VERSION ""

NS_ :

BS_:

BU_: BAP_Tester BedienDisp_vo BedienSG_hi CGS DDA Gateway Gateway_PAG GurtMikrofon OTA_FC ZR_High ZR_LIMU ZR_MIB_TOP_ab_Gen3 ZR_Standard

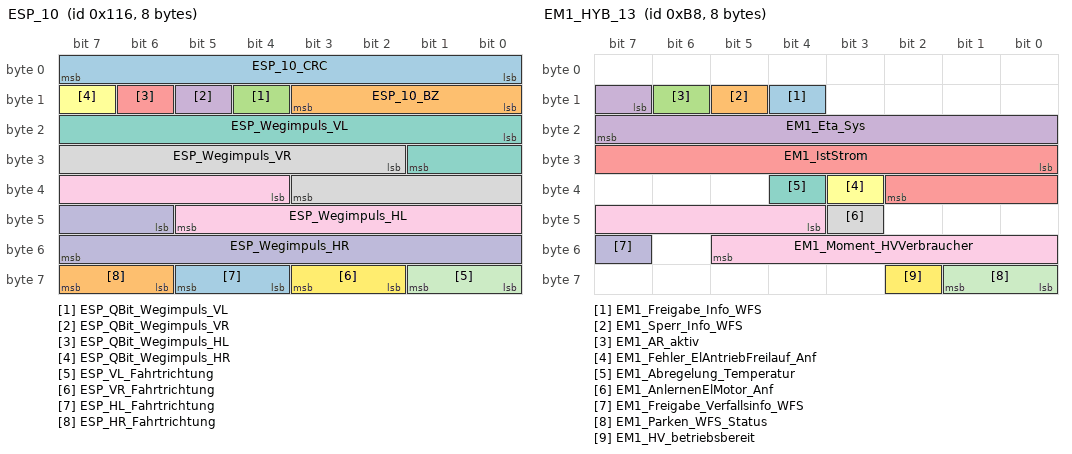
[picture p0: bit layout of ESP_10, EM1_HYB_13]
BO_ 278 ESP_10: 8 Gateway_MQB
 SG_ ESP_10_CRC : 0|8@1+ (1,0) [0|255] "" Airbag_MQB,Motor_Diesel_MQB,Motor_Hybrid_MQB,Motor_Otto_MQB
 SG_ ESP_10_BZ : 8|4@1+ (1,0) [0|15] "" Airbag_MQB,Motor_Diesel_MQB,Motor_Hybrid_MQB,Motor_Otto_MQB
 SG_ ESP_QBit_Wegimpuls_VL : 12|1@1+ (1,0) [0|1] "" Getriebe_DQ_Hybrid_MQB,Getriebe_DQ_MQB,Motor_Diesel_MQB,Motor_Hybrid_MQB,Motor_Otto_MQB
 SG_ ESP_QBit_Wegimpuls_VR : 13|1@1+ (1,0) [0|1] "" Getriebe_DQ_Hybrid_MQB,Getriebe_DQ_MQB,Motor_Diesel_MQB,Motor_Hybrid_MQB,Motor_Otto_MQB
 SG_ ESP_QBit_Wegimpuls_HL : 14|1@1+ (1,0) [0|1] "" Getriebe_DQ_Hybrid_MQB,Getriebe_DQ_MQB,Motor_Diesel_MQB,Motor_Hybrid_MQB,Motor_Otto_MQB
 SG_ ESP_QBit_Wegimpuls_HR : 15|1@1+ (1,0) [0|1] "" Getriebe_DQ_Hybrid_MQB,Getriebe_DQ_MQB,Motor_Diesel_MQB,Motor_Hybrid_MQB,Motor_Otto_MQB
 SG_ ESP_Wegimpuls_VL : 16|10@1+ (1,0) [0|1000] "" Getriebe_DQ_Hybrid_MQB,Getriebe_DQ_MQB,Motor_Diesel_MQB,Motor_Hybrid_MQB,Motor_Otto_MQB
 SG_ ESP_Wegimpuls_VR : 26|10@1+ (1,0) [0|1000] "" Getriebe_DQ_Hybrid_MQB,Getriebe_DQ_MQB,Motor_Diesel_MQB,Motor_Hybrid_MQB,Motor_Otto_MQB
 SG_ ESP_Wegimpuls_HL : 36|10@1+ (1,0) [0|1000] "" Getriebe_DQ_Hybrid_MQB,Getriebe_DQ_MQB,Motor_Diesel_MQB,Motor_Hybrid_MQB,Motor_Otto_MQB
 SG_ ESP_Wegimpuls_HR : 46|10@1+ (1,0) [0|1000] "" Getriebe_DQ_Hybrid_MQB,Getriebe_DQ_MQB,Motor_Diesel_MQB,Motor_Hybrid_MQB,Motor_Otto_MQB
 SG_ ESP_VL_Fahrtrichtung : 56|2@1+ (1,0) [0|3] "" Airbag_MQB,Getriebe_DQ_Hybrid_MQB,Getriebe_DQ_MQB,Motor_Diesel_MQB,Motor_Hybrid_MQB,Motor_Otto_MQB
 SG_ ESP_VR_Fahrtrichtung : 58|2@1+ (1,0) [0|3] "" Airbag_MQB,Getriebe_DQ_Hybrid_MQB,Getriebe_DQ_MQB,Motor_Diesel_MQB,Motor_Hybrid_MQB,Motor_Otto_MQB
 SG_ ESP_HL_Fahrtrichtung : 60|2@1+ (1,0) [0|3] "" Airbag_MQB,Getriebe_DQ_Hybrid_MQB,Getriebe_DQ_MQB,Motor_Diesel_MQB,Motor_Hybrid_MQB,Motor_Otto_MQB
 SG_ ESP_HR_Fahrtrichtung : 62|2@1+ (1,0) [0|3] "" Airbag_MQB,Getriebe_DQ_Hybrid_MQB,Getriebe_DQ_MQB,Motor_Diesel_MQB,Motor_Hybrid_MQB,Motor_Otto_MQB

BO_ 253 ESP_21: 8 Gateway_MQB
 SG_ CHECKSUM : 0|8@1+ (1,0) [0|255] "" Airbag_MQB,Getriebe_DQ_Hybrid_MQB,Getriebe_DQ_MQB,LEH_MQB,Motor_Diesel_MQB,Motor_Hybrid_MQB,Motor_Otto_MQB
 SG_ COUNTER : 8|4@1+ (1,0) [0|15] "" Airbag_MQB,BMS_MQB,Getriebe_DQ_Hybrid_MQB,Getriebe_DQ_MQB,LEH_MQB,Motor_Diesel_MQB,Motor_Hybrid_MQB,Motor_Otto_MQB
 SG_ BR_Eingriffsmoment : 12|10@1+ (1,-509) [-509|509] "Unit_NewtoMeter" Motor_Diesel_MQB,Motor_Hybrid_MQB,Motor_Otto_MQB
 SG_ ESP_v_Signal : 32|16@1+ (0.01,0) [0|655.32] "Unit_KiloMeterPerHour" Airbag_MQB,BMS_MQB,Getriebe_DQ_Hybrid_MQB,Getriebe_DQ_MQB,LEH_MQB,Motor_Diesel_MQB,Motor_Hybrid_MQB,Motor_Otto_MQB,SAK_MQB
 SG_ ASR_Tastung_passiv : 48|1@1+ (1,0) [0|1] "" Airbag_MQB,Getriebe_DQ_Hybrid_MQB,Getriebe_DQ_MQB,Motor_Diesel_MQB,Motor_Hybrid_MQB,Motor_Otto_MQB
 SG_ ESP_Tastung_passiv : 49|1@1+ (1,0) [0|1] "" Airbag_MQB,Getriebe_DQ_Hybrid_MQB,Getriebe_DQ_MQB,Motor_Diesel_MQB,Motor_Hybrid_MQB,Motor_Otto_MQB
 SG_ ESP_Systemstatus : 50|1@1+ (1,0) [0|1] "" Airbag_MQB,Getriebe_DQ_Hybrid_MQB,Getriebe_DQ_MQB,Motor_Diesel_MQB,Motor_Hybrid_MQB,Motor_Otto_MQB
 SG_ ASR_Schalteingriff : 51|2@1+ (1,0) [0|3] "" Getriebe_DQ_Hybrid_MQB,Getriebe_DQ_MQB
 SG_ ESP_Haltebestaetigung : 53|1@1+ (1,0) [0|1] "" Motor_Diesel_MQB,Motor_Hybrid_MQB,Motor_Otto_MQB
 SG_ ESP_QBit_v_Signal : 55|1@1+ (1,0) [0|1] "" Airbag_MQB,Getriebe_DQ_Hybrid_MQB,Getriebe_DQ_MQB,LEH_MQB,Motor_Diesel_MQB,Motor_Hybrid_MQB,Motor_Otto_MQB
 SG_ ABS_Bremsung : 56|1@1+ (1,0) [0|1] "" Airbag_MQB,Getriebe_DQ_Hybrid_MQB,Getriebe_DQ_MQB,Motor_Diesel_MQB,Motor_Hybrid_MQB,Motor_Otto_MQB
 SG_ ASR_Anf : 57|1@1+ (1,0) [0|1] "" Getriebe_DQ_Hybrid_MQB,Getriebe_DQ_MQB,Motor_Diesel_MQB,Motor_Hybrid_MQB,Motor_Otto_MQB
 SG_ MSR_Anf : 58|1@1+ (1,0) [0|1] "" Getriebe_DQ_Hybrid_MQB,Getriebe_DQ_MQB,Motor_Diesel_MQB,Motor_Hybrid_MQB,Motor_Otto_MQB
 SG_ EBV_Eingriff : 59|1@1+ (1,0) [0|1] "" Motor_Diesel_MQB,Motor_Hybrid_MQB,Motor_Otto_MQB
 SG_ EDS_Eingriff : 60|1@1+ (1,0) [0|1] "" Getriebe_DQ_Hybrid_MQB,Getriebe_DQ_MQB,Motor_Diesel_MQB,Motor_Hybrid_MQB,Motor_Otto_MQB
 SG_ ESP_Eingriff : 61|1@1+ (1,0) [0|1] "" Airbag_MQB,Getriebe_DQ_Hybrid_MQB,Getriebe_DQ_MQB,Motor_Diesel_MQB,Motor_Hybrid_MQB,Motor_Otto_MQB
 SG_ ESP_ASP : 62|1@1+ (1,0) [0|1] "" Getriebe_DQ_Hybrid_MQB,Getriebe_DQ_MQB,Motor_Diesel_MQB,Motor_Hybrid_MQB,Motor_Otto_MQB
 SG_ ESP_Anhaltevorgang_ACC_aktiv : 63|1@1+ (1,0) [0|1] "" Motor_Diesel_MQB,Motor_Hybrid_MQB,Motor_Otto_MQB

BO_ 795 ESP_24: 8 Gateway
 SG_ ESP_24_CRC : 0|8@1+ (1,0) [0|255] ""  Sub_Gateway
 SG_ ESP_24_BZ : 8|4@1+ (1,0) [0|15] ""  Sub_Gateway
 SG_ ESP_Lampe : 12|1@1+ (1,0) [0|1] ""  Sub_Gateway
 SG_ ABS_Lampe : 13|1@1+ (1,0) [0|1] ""  Sub_Gateway
 SG_ BK_Lampe_02 : 14|2@1+ (1,0) [0|3] ""  Sub_Gateway
 SG_ TC_Lampe : 16|1@1+ (1,0) [0|1] ""  Sub_Gateway
 SG_ ESP_m_Raddrehz : 17|15@1+ (0.002,0) [0|65.278] "Unit_Hertz"  Sub_Gateway
 SG_ ESP_Textanzeigen_03 : 32|5@1+ (1,0) [0|31] ""  Sub_Gateway
 SG_ ESP_Meldungen : 37|3@1+ (1,0) [0|7] ""  Sub_Gateway
 SG_ ESP_Wegimp_VA : 40|11@1+ (1,0) [0|2047] ""  Sub_Gateway
 SG_ ESP_Fehlerstatus_Wegimp : 51|1@1+ (1,0) [0|1] ""  Sub_Gateway
 SG_ ESP_Wegimp_Ueberlauf : 52|1@1+ (1,0) [0|1] ""  Sub_Gateway
 SG_ ESP_QBit_Wegimp_VA : 53|1@1+ (1,0) [0|1] ""  Sub_Gateway
 SG_ ESP_HDC_Geschw_Farbe : 54|1@1+ (1,0) [0|1] ""  Sub_Gateway
 SG_ ESP_Off_Lampe : 55|1@1+ (1,0) [0|1] ""  Sub_Gateway
 SG_ ESP_HDC_Regelgeschw : 56|7@1+ (0.32,0) [0.32|39.68] "Unit_KiloMeterPerHour"  Sub_Gateway
 SG_ ESP_BKV_Warnung : 63|1@1+ (1,0) [0|1] ""  Sub_Gateway

BO_ 184 EM1_HYB_13: 8 Gateway
 SG_ EM1_Freigabe_Info_WFS : 12|1@1+ (1,0) [0|1] ""  Sub_Gateway
 SG_ EM1_Sperr_Info_WFS : 13|1@1+ (1,0) [0|1] ""  Sub_Gateway
 SG_ EM1_AR_aktiv : 14|1@1+ (1,0) [0|1] ""  Sub_Gateway
 SG_ EM1_Eta_Sys : 15|9@1+ (0.2,0) [0|101.8] "Unit_PerCent"  Sub_Gateway
 SG_ EM1_IstStrom : 24|11@1+ (1,-1023) [-1023|1022] "Unit_Amper"  Sub_Gateway
 SG_ EM1_Fehler_ElAntriebFreilauf_Anf : 35|1@1+ (1,0) [0|1] ""  Sub_Gateway
 SG_ EM1_Abregelung_Temperatur : 36|1@1+ (1,0) [0|1] ""  Sub_Gateway
 SG_ EM1_AnlernenElMotor_Anf : 43|1@1+ (1,0) [0|1] ""  Sub_Gateway
 SG_ EM1_Moment_HVVerbraucher : 44|10@1+ (1,-511) [-511|511] "Unit_NewtoMeter"  Sub_Gateway
 SG_ EM1_Freigabe_Verfallsinfo_WFS : 55|1@1+ (1,0) [0|1] ""  Sub_Gateway
 SG_ EM1_Parken_WFS_Status : 56|2@1+ (1,0) [0|3] ""  Sub_Gateway
 SG_ EM1_HV_betriebsbereit : 58|1@1+ (1,0) [0|1] ""  Sub_Gateway

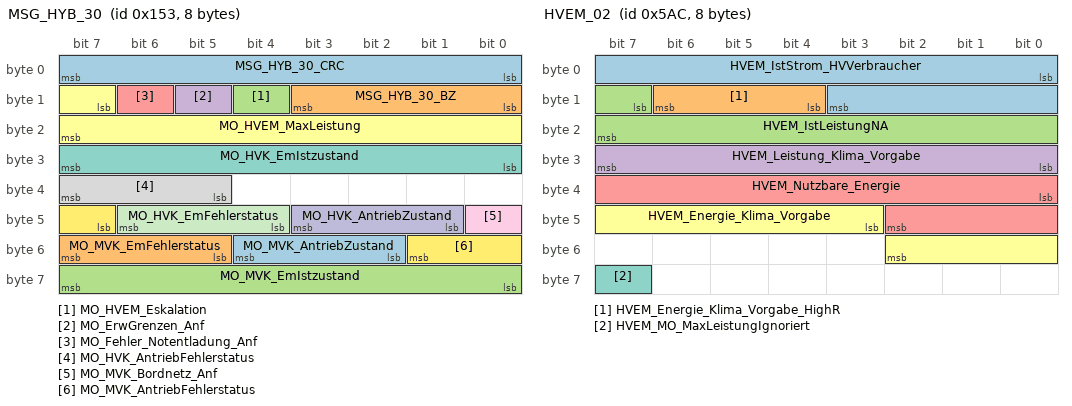
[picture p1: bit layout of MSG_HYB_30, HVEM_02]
BO_ 339 MSG_HYB_30: 8 Gateway
 SG_ MSG_HYB_30_CRC : 0|8@1+ (1,0) [0|255] ""  Ladegeraet_Konzern
 SG_ MSG_HYB_30_BZ : 8|4@1+ (1,0) [0|15] ""  Ladegeraet_Konzern
 SG_ MO_HVEM_Eskalation : 12|1@1+ (1,0) [0|1] "" Vector__XXX
 SG_ MO_ErwGrenzen_Anf : 13|1@1+ (1,0) [0|1] ""  BMC_MLBevo
 SG_ MO_Fehler_Notentladung_Anf : 14|1@1+ (1,0) [0|1] "" Vector__XXX
 SG_ MO_HVEM_MaxLeistung : 15|9@1+ (50,0) [0|25450] "Unit_Watt" Vector__XXX
 SG_ MO_HVK_EmIstzustand : 24|8@1+ (1,0) [0|255] "" Vector__XXX
 SG_ MO_HVK_AntriebFehlerstatus : 37|3@1+ (1,0) [0|7] "" Vector__XXX
 SG_ MO_MVK_Bordnetz_Anf : 40|1@1+ (1,0) [0|1] "" Vector__XXX
 SG_ MO_HVK_AntriebZustand : 41|3@1+ (1,0) [0|7] ""  TME
 SG_ MO_HVK_EmFehlerstatus : 44|3@1+ (1,0) [0|7] "" Vector__XXX
 SG_ MO_MVK_AntriebFehlerstatus : 47|3@1+ (1,0) [0|7] "" Vector__XXX
 SG_ MO_MVK_AntriebZustand : 50|3@1+ (1,0) [0|7] "" Vector__XXX
 SG_ MO_MVK_EmFehlerstatus : 53|3@1+ (1,0) [0|7] "" Vector__XXX
 SG_ MO_MVK_EmIstzustand : 56|8@1+ (1,0) [0|255] "" Vector__XXX

BO_ 1452 HVEM_02: 8 Gateway
 SG_ HVEM_IstStrom_HVVerbraucher : 0|12@1+ (0.1,-204.7) [-204.7|204.6] "Unit_Amper" Vector__XXX
 SG_ HVEM_Energie_Klima_Vorgabe_HighR : 12|3@1+ (10,0) [0|50] "Unit_WattHour"  TME
 SG_ HVEM_IstLeistungNA : 15|9@1+ (50,0) [0|25450] "Unit_Watt" Vector__XXX
 SG_ HVEM_Leistung_Klima_Vorgabe : 24|8@1+ (50,0) [0|12650] "Unit_Watt"  TME
 SG_ HVEM_Nutzbare_Energie : 32|11@1+ (50,0) [0|102200] "Unit_WattHour"  Ladegeraet_Konzern
 SG_ HVEM_Energie_Klima_Vorgabe : 43|8@1+ (50,0) [0|12650] "Unit_WattHour"  TME
 SG_ HVEM_MO_MaxLeistungIgnoriert : 63|1@1+ (1,0) [0|1] "" Vector__XXX

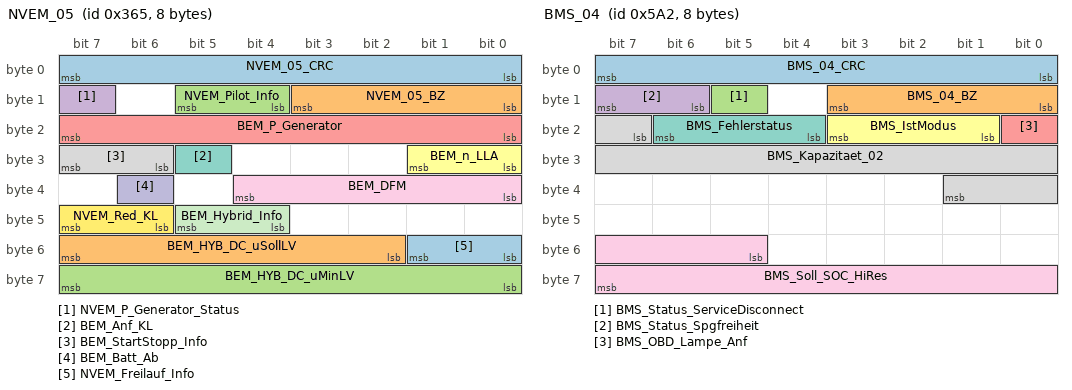
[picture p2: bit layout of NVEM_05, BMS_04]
BO_ 869 NVEM_05: 8 Gateway
 SG_ NVEM_05_CRC : 0|8@1+ (1,0) [0|255] "" Vector__XXX
 SG_ NVEM_05_BZ : 8|4@1+ (1,0) [0|15] "" Vector__XXX
 SG_ NVEM_Pilot_Info : 12|2@1+ (1,0) [0|3] "" Vector__XXX
 SG_ NVEM_P_Generator_Status : 15|1@1+ (1,0) [0|1] "" Vector__XXX
 SG_ BEM_P_Generator : 16|8@1+ (50,0) [0|12700] "Unit_Watt" Vector__XXX
 SG_ BEM_n_LLA : 24|2@1+ (1,0) [0|3] "" Vector__XXX
 SG_ BEM_Anf_KL : 29|1@1+ (1,0) [0|1] "" Vector__XXX
 SG_ BEM_StartStopp_Info : 30|2@1+ (1,0) [0|3] "" Vector__XXX
 SG_ BEM_DFM : 32|5@1+ (3.225,0.025) [0.025|100] "" Vector__XXX
 SG_ BEM_Batt_Ab : 38|1@1+ (1,0) [0|1] ""  DCDC_800V_PAG,DCDC_IHEV
 SG_ BEM_Hybrid_Info : 44|2@1+ (1,0) [0|3] "" Vector__XXX
 SG_ NVEM_Red_KL : 46|2@1+ (1,0) [0|3] ""  TME
 SG_ NVEM_Freilauf_Info : 48|2@1+ (1,0) [0|3] "" Vector__XXX
 SG_ BEM_HYB_DC_uSollLV : 50|6@1+ (0.1,10.6) [10.6|16] "Unit_Volt"  DCDC_800V_PAG,DCDC_HV,LE_MLBevo
 SG_ BEM_HYB_DC_uMinLV : 56|8@1+ (0.1,0) [0|25.3] "Unit_Volt" Vector__XXX

BO_ 1442 BMS_04: 8 BMC_MLBevo
 SG_ BMS_04_CRC : 0|8@1+ (1,0) [0|255] ""  Gateway,Gateway_PAG,Sub_Gateway
 SG_ BMS_04_BZ : 8|4@1+ (1,0) [0|15] ""  Gateway,Gateway_PAG,Sub_Gateway
 SG_ BMS_Status_ServiceDisconnect : 13|1@1+ (1,0) [0|1] ""  DCDC_800V_PAG,DCDC_HV,Gateway,Gateway_PAG,Sub_Gateway
 SG_ BMS_Status_Spgfreiheit : 14|2@1+ (1,0) [0|3] ""  Gateway,Gateway_PAG,Sub_Gateway
 SG_ BMS_OBD_Lampe_Anf : 16|1@1+ (1,0) [0|1] ""  Gateway,Gateway_PAG,Sub_Gateway
 SG_ BMS_IstModus : 17|3@1+ (1,0) [0|7] ""  AWC,Gateway,Gateway_PAG,Ladegeraet_Konzern,LE1,LE2,LE2_3_MLBevo_LB,Sub_Gateway,TME
 SG_ BMS_Fehlerstatus : 20|3@1+ (1,0) [0|7] ""  AWC,DCDC_800V_PAG,DCDC_HV,Gateway,Gateway_PAG,Ladegeraet_Konzern,Sub_Gateway
 SG_ BMS_Kapazitaet_02 : 23|11@1+ (0.2,0) [0|409.2] "Unit_AmperHour"  Gateway,Gateway_PAG,Ladegeraet_Konzern,Sub_Gateway
 SG_ BMS_Soll_SOC_HiRes : 53|11@1+ (0.05,0) [0|100] "Unit_PerCent"  Gateway,Gateway_PAG,Sub_Gateway

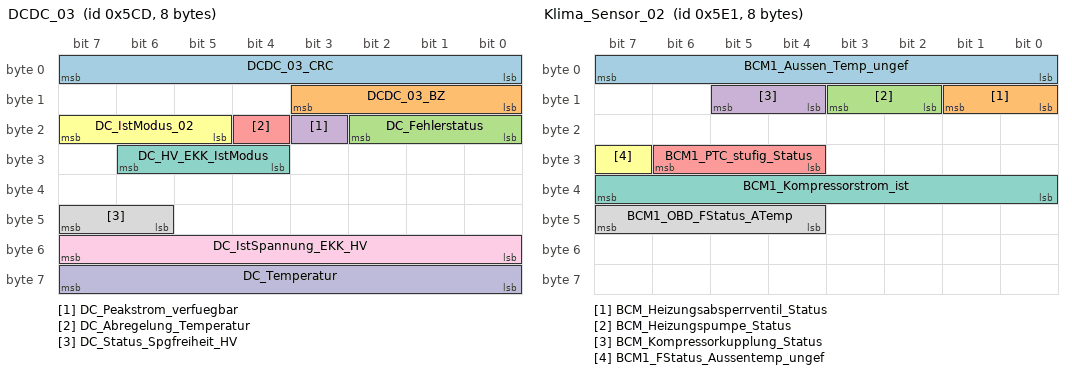
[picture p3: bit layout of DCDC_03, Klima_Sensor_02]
BO_ 1485 DCDC_03: 8 DCDC_800V_PAG
 SG_ DCDC_03_CRC : 0|8@1+ (1,0) [0|255] ""  Gateway,Gateway_PAG,Sub_Gateway
 SG_ DCDC_03_BZ : 8|4@1+ (1,0) [0|15] ""  Gateway,Gateway_PAG,Sub_Gateway
 SG_ DC_Fehlerstatus : 16|3@1+ (1,0) [0|7] ""  Gateway,Gateway_PAG,Sub_Gateway
 SG_ DC_Peakstrom_verfuegbar : 19|1@1+ (1,0) [0|1] ""  Gateway,Gateway_PAG,Sub_Gateway
 SG_ DC_Abregelung_Temperatur : 20|1@1+ (1,0) [0|1] ""  Gateway_PAG,Sub_Gateway,TME
 SG_ DC_IstModus_02 : 21|3@1+ (1,0) [0|7] ""  DCDC_HV_02,Gateway,Gateway_PAG,Ladegeraet_Konzern,Sub_Gateway,TME
 SG_ DC_HV_EKK_IstModus : 28|3@1+ (1,0) [0|7] ""  Gateway,Gateway_PAG,Sub_Gateway,TME
 SG_ DC_Status_Spgfreiheit_HV : 46|2@1+ (1,0) [0|3] ""  Gateway,Gateway_PAG,Sub_Gateway
 SG_ DC_IstSpannung_EKK_HV : 48|8@1+ (2,0) [0|508] "Unit_Volt"  Gateway,Gateway_PAG,Sub_Gateway
 SG_ DC_Temperatur : 56|8@1+ (1,-40) [-40|213] "Unit_DegreCelsi"  Gateway,Gateway_PAG,Sub_Gateway,TME

BO_ 1505 Klima_Sensor_02: 8 Gateway
 SG_ BCM1_Aussen_Temp_ungef : 0|8@1+ (0.5,-50) [-50|76] "Unit_DegreCelsi"  BMC_MLBevo,BMS_NV,FCU_MLBevo_FCEV,Ladegeraet_Konzern,TME
 SG_ BCM_Heizungsabsperrventil_Status : 8|2@1+ (1,0) [0|3] "" Vector__XXX
 SG_ BCM_Heizungspumpe_Status : 10|2@1+ (1,0) [0|3] "" Vector__XXX
 SG_ BCM_Kompressorkupplung_Status : 12|2@1+ (1,0) [0|3] "" Vector__XXX
 SG_ BCM1_PTC_stufig_Status : 28|3@1+ (1,0) [0|7] "" Vector__XXX
 SG_ BCM1_FStatus_Aussentemp_ungef : 31|1@1+ (1,0) [0|1] ""  TME
 SG_ BCM1_Kompressorstrom_ist : 32|8@1+ (4,0) [0|1000] "Unit_MilliAmper" Vector__XXX
 SG_ BCM1_OBD_FStatus_ATemp : 44|4@1+ (1,0) [0|15] ""  BMC_MLBevo,Ladegeraet_Konzern,TME

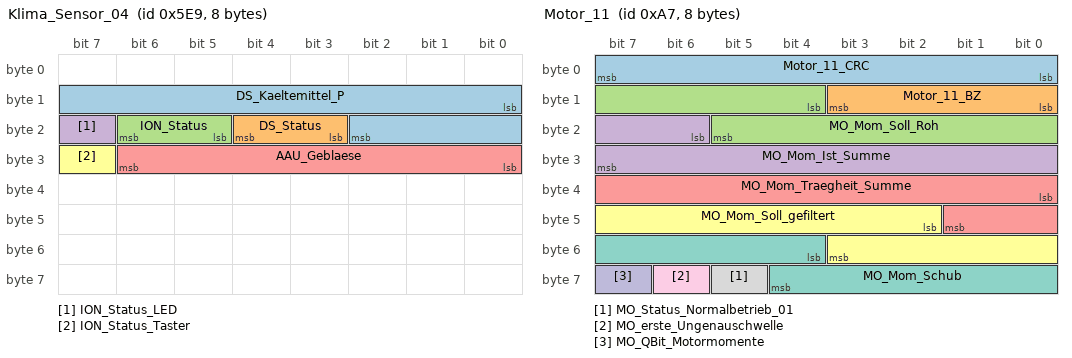
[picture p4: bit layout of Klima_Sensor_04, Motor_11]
BO_ 1513 Klima_Sensor_04: 8 Gateway
 SG_ DS_Kaeltemittel_P : 8|11@1+ (0.0161,0) [0|32.9245] "Unit_Bar"  TME
 SG_ DS_Status : 19|2@1+ (1,0) [0|3] ""  TME
 SG_ ION_Status : 21|2@1+ (1,0) [0|3] "" Vector__XXX
 SG_ ION_Status_LED : 23|1@1+ (1,0) [0|1] "" Vector__XXX
 SG_ AAU_Geblaese : 24|7@1+ (1,0) [0|100] "Unit_PerCent" Vector__XXX
 SG_ ION_Status_Taster : 31|1@1+ (1,0) [0|1] "" Vector__XXX

BO_ 1600 Motor_07: 8 Motor_Diesel_MQB
 SG_ MO_QBit_Ansaugluft_Temp : 0|1@1+ (1,0) [0|1] "" Gateway_MQB
 SG_ MO_QBit_Oel_Temp : 1|1@1+ (1,0) [0|1] "" Gateway_MQB,Getriebe_DQ_Hybrid_MQB,Getriebe_DQ_MQB
 SG_ MO_QBit_Kuehlmittel_Temp : 2|1@1+ (1,0) [0|1] "" Gateway_MQB,Getriebe_DQ_Hybrid_MQB,Getriebe_DQ_MQB,LEH_MQB
 SG_ MO_Stellgliedtest_Soundaktuator : 3|1@1+ (1,0) [0|1] "" Gateway_MQB
 SG_ MO_HYB_Fehler_HV_Netz : 4|1@1+ (1,0) [0|1] "" Gateway_MQB
 SG_ MO_aktives_Getriebeheizen : 5|1@1+ (1,0) [0|1] "" Gateway_MQB,Getriebe_DQ_Hybrid_MQB,Getriebe_DQ_MQB
 SG_ MO_Absperrventil_oeffnen : 6|2@1+ (1,0) [0|3] "" Gateway_MQB
 SG_ MO_Ansaugluft_Temp : 8|8@1+ (0.75,-48) [-48|141.75] "Unit_DegreCelsi" Gateway_MQB
 SG_ MO_Oel_Temp : 16|8@1+ (1,-60) [-60|192] "Unit_DegreCelsi" Gateway_MQB,Getriebe_DQ_Hybrid_MQB,Getriebe_DQ_MQB
 SG_ MO_Kuehlmittel_Temp : 24|8@1+ (0.75,-48) [-48|141.75] "Unit_DegreCelsi" Gateway_MQB,Getriebe_DQ_Hybrid_MQB,Getriebe_DQ_MQB,LEH_MQB
 SG_ MO_Hoeheninfo : 32|8@1+ (0.00781,0) [0|1.98374] "" Gateway_MQB,Getriebe_DQ_Hybrid_MQB,Getriebe_DQ_MQB
 SG_ MO_Kennfeldk : 40|1@1+ (1,0) [0|1] "" Gateway_MQB
 SG_ MO_Versionsinfo : 41|6@1+ (1,0) [0|63] "" Gateway_MQB
 SG_ MO_Getriebe_kuehlen : 47|1@1+ (1,0) [0|1] "" Gateway_MQB,Getriebe_DQ_Hybrid_MQB,Getriebe_DQ_MQB
 SG_ MO_Mom_Traegheit_02 : 48|5@1+ (0.01,0) [0|0.31] "Unit_KiloGramMeterSquar" Gateway_MQB,Getriebe_DQ_Hybrid_MQB,Getriebe_DQ_MQB
 SG_ MO_Heizungspumpenansteuerung : 53|4@1+ (10,0) [0|100] "Unit_PerCent" Gateway_MQB
 SG_ MO_SpannungsAnf : 57|1@1+ (1,0) [0|1] "" Gateway_MQB
 SG_ MO_Nachlaufzeit_Heizungspumpe : 58|6@1+ (15,0) [0|945] "Unit_Secon" Gateway_MQB

BO_ 167 Motor_11: 8 Motor_Diesel_MQB
 SG_ Motor_11_CRC : 0|8@1+ (1,0) [0|255] "" Gateway_MQB,Getriebe_DQ_Hybrid_MQB,Getriebe_DQ_MQB
 SG_ Motor_11_BZ : 8|4@1+ (1,0) [0|15] "" Gateway_MQB,Getriebe_DQ_Hybrid_MQB,Getriebe_DQ_MQB
 SG_ MO_Mom_Soll_Roh : 12|10@1+ (1,-509) [-509|509] "Unit_NewtoMeter" Gateway_MQB,Getriebe_DQ_Hybrid_MQB,Getriebe_DQ_MQB
 SG_ MO_Mom_Ist_Summe : 22|10@1+ (1,-509) [-509|509] "Unit_NewtoMeter" Gateway_MQB,Getriebe_DQ_Hybrid_MQB,Getriebe_DQ_MQB,SAK_MQB
 SG_ MO_Mom_Traegheit_Summe : 32|10@1+ (1,-509) [-509|509] "Unit_NewtoMeter" Gateway_MQB,Getriebe_DQ_Hybrid_MQB,Getriebe_DQ_MQB
 SG_ MO_Mom_Soll_gefiltert : 42|10@1+ (1,-509) [-509|509] "Unit_NewtoMeter" Gateway_MQB,Getriebe_DQ_Hybrid_MQB,Getriebe_DQ_MQB
 SG_ MO_Mom_Schub : 52|9@1+ (1,-509) [-509|0] "Unit_NewtoMeter" Gateway_MQB,Getriebe_DQ_Hybrid_MQB,Getriebe_DQ_MQB
 SG_ MO_Status_Normalbetrieb_01 : 61|1@1+ (1,0) [0|1] "" Gateway_MQB,Getriebe_DQ_Hybrid_MQB,Getriebe_DQ_MQB
 SG_ MO_erste_Ungenauschwelle : 62|1@1+ (1,0) [0|1] "" Gateway_MQB
 SG_ MO_QBit_Motormomente : 63|1@1+ (1,0) [0|1] "" Gateway_MQB,Getriebe_DQ_Hybrid_MQB,Getriebe_DQ_MQB

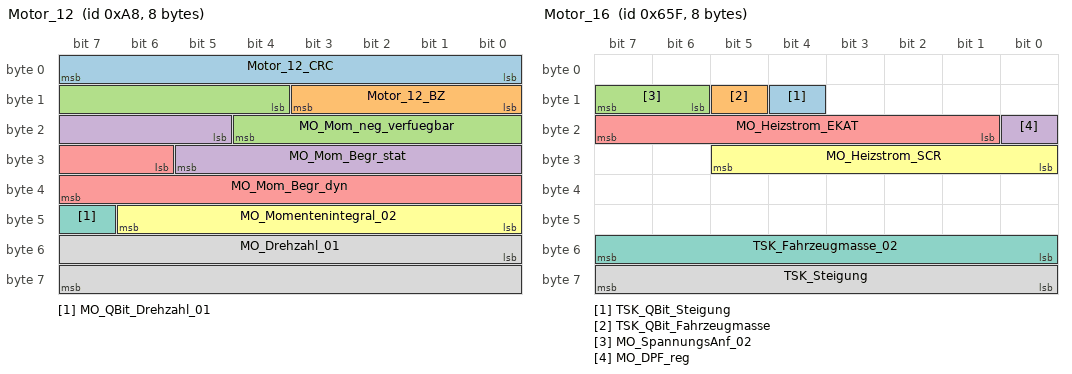
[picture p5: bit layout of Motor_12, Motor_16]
BO_ 168 Motor_12: 8 Motor_Diesel_MQB
 SG_ Motor_12_CRC : 0|8@1+ (1,0) [0|255] "" Gateway_MQB,Getriebe_DQ_Hybrid_MQB,Getriebe_DQ_MQB,LEH_MQB
 SG_ Motor_12_BZ : 8|4@1+ (1,0) [0|15] "" BMS_MQB,Gateway_MQB,Getriebe_DQ_Hybrid_MQB,Getriebe_DQ_MQB,LEH_MQB
 SG_ MO_Mom_neg_verfuegbar : 12|9@1+ (1,-509) [-509|0] "Unit_NewtoMeter" Gateway_MQB
 SG_ MO_Mom_Begr_stat : 21|9@1+ (1,0) [0|509] "Unit_NewtoMeter" Gateway_MQB,Getriebe_DQ_Hybrid_MQB,Getriebe_DQ_MQB
 SG_ MO_Mom_Begr_dyn : 30|10@1+ (1,-509) [-509|509] "Unit_NewtoMeter" Gateway_MQB
 SG_ MO_Momentenintegral_02 : 40|7@1+ (1,0) [0|100] "Unit_PerCent" Gateway_MQB,Getriebe_DQ_Hybrid_MQB,Getriebe_DQ_MQB
 SG_ MO_QBit_Drehzahl_01 : 47|1@1+ (1,0) [0|1] "" BMS_MQB,Gateway_MQB,Getriebe_DQ_Hybrid_MQB,Getriebe_DQ_MQB,LEH_MQB
 SG_ MO_Drehzahl_01 : 48|16@1+ (0.25,0) [0|16383] "Unit_MinutInver" BMS_MQB,Gateway_MQB,Getriebe_DQ_Hybrid_MQB,Getriebe_DQ_MQB,LEH_MQB,SAK_MQB

BO_ 958 Motor_14: 8 Gateway
 SG_ Motor_14_CRC : 0|8@1+ (1,0) [0|255] ""  Sub_Gateway
 SG_ Motor_14_BZ : 8|4@1+ (1,0) [0|15] ""  Sub_Gateway
 SG_ MO_StartStopp_Status : 12|2@1+ (1,0) [0|3] ""  Sub_Gateway,TME
 SG_ MO_StartStopp_Wiederstart : 14|1@1+ (1,0) [0|1] ""  BMS_NV,Sub_Gateway,TME
 SG_ MO_StartStopp_Motorstopp : 15|1@1+ (1,0) [0|1] ""  BMS_NV,Sub_Gateway,TME
 SG_ MO_Freig_Reku : 16|2@1+ (1,0) [0|3] ""  Sub_Gateway
 SG_ MO_Kl_75 : 18|1@1+ (1,0) [0|1] ""  Sub_Gateway,TME
 SG_ MO_Kl_50 : 19|1@1+ (1,0) [0|1] ""  DCDC_IHEV,Ladegeraet_Konzern,Sub_Gateway
 SG_ MO_Gangposition : 20|4@1+ (1,0) [0|15] ""  AWC,Sub_Gateway,TME
 SG_ MO_StartStopp_Fahrerwunsch : 24|2@1+ (1,0) [0|3] ""  Sub_Gateway,TME
 SG_ MO_HYB_Fahrbereitschaft : 26|1@1+ (1,0) [0|1] ""  AWC,BMS_NV,Ladegeraet_Konzern,Sub_Gateway,TME
 SG_ MO_Ext_E_Fahrt_aktiv : 27|1@1+ (1,0) [0|1] ""  Sub_Gateway,TME
 SG_ MO_Fahrer_bremst : 28|1@1+ (1,0) [0|1] ""  Sub_Gateway
 SG_ MO_QBit_Fahrer_bremst : 29|1@1+ (1,0) [0|1] ""  Sub_Gateway
 SG_ MO_BLS : 30|1@1+ (1,0) [0|1] ""  Sub_Gateway
 SG_ MO_Konsistenz_Bremsped : 31|1@1+ (1,0) [0|1] ""  Sub_Gateway
 SG_ MO_KomFehler_ESP : 32|1@1+ (1,0) [0|1] ""  Sub_Gateway
 SG_ MO_Klima_Eingr : 33|2@1+ (1,0) [0|3] ""  Sub_Gateway,TME
 SG_ MO_Aussp_Anlass : 35|1@1+ (1,0) [0|1] ""  Sub_Gateway
 SG_ MO_Freig_Anlass : 36|1@1+ (1,0) [0|1] ""  Sub_Gateway
 SG_ MO_Kuppl_schalter : 37|1@1+ (1,0) [0|1] ""  Sub_Gateway
 SG_ MO_Interlock : 38|1@1+ (1,0) [0|1] ""  Sub_Gateway
 SG_ MO_Motor_laeuft : 39|1@1+ (1,0) [0|1] ""  Sub_Gateway,TME
 SG_ MO_Kickdown : 40|1@1+ (1,0) [0|1] ""  Sub_Gateway,TME
 SG_ MO_QBit_KL_75 : 41|1@1+ (1,0) [0|1] ""  Sub_Gateway
 SG_ MO_EKlKomLeiRed : 42|2@1+ (1,0) [0|3] ""  Sub_Gateway
 SG_ MO_Handshake_STH : 44|1@1+ (1,0) [0|1] ""  Sub_Gateway
 SG_ MO_BKV_Unterdruckwarnung : 45|1@1+ (1,0) [0|1] ""  Sub_Gateway
 SG_ MO_Freigabe_Segeln : 46|1@1+ (1,0) [0|1] ""  Sub_Gateway
 SG_ MO_PTC_Status : 47|3@1+ (1,0) [0|7] ""  Sub_Gateway
 SG_ MO_QBit_Gangposition : 50|1@1+ (1,0) [0|1] ""  Sub_Gateway
 SG_ MO_Signalquelle_Gangposition : 51|1@1+ (1,0) [0|1] ""  Sub_Gateway
 SG_ MO_Remotestart_Betrieb : 52|1@1+ (1,0) [0|1] ""  Sub_Gateway
 SG_ MO_Remotestart_moeglich : 53|1@1+ (1,0) [0|1] ""  Sub_Gateway
 SG_ MO_FMAus_aktiv : 55|1@1+ (1,0) [0|1] ""  BMS_NV,Sub_Gateway
 SG_ MO_FMAus_Startvariante : 56|2@1+ (1,0) [0|3] ""  Sub_Gateway
 SG_ MO_BMS_NV_Anf_stuetzen : 58|1@1+ (1,0) [0|1] ""  Sub_Gateway
 SG_ MO_Zylinderabschaltung : 59|2@1+ (1,0) [0|3] ""  Sub_Gateway
 SG_ MO_HYB_VM_aktiv : 61|1@1+ (1,0) [0|1] ""  Sub_Gateway
 SG_ MO_StartVorauss_erfuellt : 62|2@1+ (1,0) [0|3] ""  AWC,Ladegeraet_Konzern,Sub_Gateway

BO_ 1631 Motor_16: 8 Motor_Diesel_MQB
 SG_ TSK_QBit_Steigung : 12|1@1+ (1,0) [0|1] "" Gateway_MQB,Getriebe_DQ_Hybrid_MQB,Getriebe_DQ_MQB
 SG_ TSK_QBit_Fahrzeugmasse : 13|1@1+ (1,0) [0|1] "" Gateway_MQB,Getriebe_DQ_Hybrid_MQB,Getriebe_DQ_MQB
 SG_ MO_SpannungsAnf_02 : 14|2@1+ (1,0) [0|3] "" Gateway_MQB
 SG_ MO_DPF_reg : 16|1@1+ (1,0) [0|1] "" Gateway_MQB,Getriebe_DQ_Hybrid_MQB,Getriebe_DQ_MQB
 SG_ MO_Heizstrom_EKAT : 17|7@1+ (1,0) [0|126] "Unit_Amper" Gateway_MQB
 SG_ MO_Heizstrom_SCR : 24|6@1+ (1,0) [0|62] "Unit_Amper" Gateway_MQB
 SG_ TSK_Fahrzeugmasse_02 : 48|8@1+ (32,0) [0|8128] "Unit_KiloGram" Gateway_MQB,Getriebe_DQ_Hybrid_MQB,Getriebe_DQ_MQB
 SG_ TSK_Steigung : 56|8@1+ (0.8,-101.6) [-101.6|101.6] "Unit_PerCent" Gateway_MQB,Getriebe_DQ_Hybrid_MQB,Getriebe_DQ_MQB

BO_ 1648 Motor_18: 8 Gateway
 SG_ MO_max_Ladedruck : 0|6@1+ (0.1,0) [0|6.3] "Unit_Bar"  Sub_Gateway
 SG_ MO_ANC_Kennfeld_Anf : 6|2@1+ (1,0) [0|3] ""  Sub_Gateway
 SG_ MO_Bremslicht_Reku : 8|1@1+ (1,0) [0|1] ""  Sub_Gateway
 SG_ MO_StartStopp_PopUp : 9|2@1+ (1,0) [0|3] ""  Sub_Gateway
 SG_ MO1_Sperr_Info_WFS : 11|1@1+ (1,0) [0|1] ""  Sub_Gateway
 SG_ MO1_Freigabe_Info_WFS : 12|1@1+ (1,0) [0|1] ""  Sub_Gateway
 SG_ MO_EPCL : 13|3@1+ (1,0) [0|7] ""  Sub_Gateway
 SG_ MO_Zylabsch_Texte_02 : 16|4@1+ (1,0) [0|15] ""  Sub_Gateway
 SG_ MO_Fahrzeugtyp : 20|3@1+ (1,0) [0|7] ""  BMS_NV,Sub_Gateway
 SG_ MO_NMAX_Schaltanzeige : 23|9@1+ (25,0) [0|12775] "Unit_MinutInver"  Sub_Gateway
 SG_ MO_Abstellzeit : 32|8@1+ (8,0) [0|2024] "Unit_Minut"  BMS_NV,Sub_Gateway,TME
 SG_ MO_Abstellzeit_Status : 40|2@1+ (1,0) [0|3] ""  BMS_NV,Sub_Gateway,TME
 SG_ MO1_Freigabe_Verfallsinfo_WFS : 42|1@1+ (1,0) [0|1] ""  Sub_Gateway
 SG_ MO_Hybrid_StartStopp_LED : 43|2@1+ (1,0) [0|3] ""  Sub_Gateway
 SG_ MO_Fehler_Zylabsch : 45|2@1+ (1,0) [0|3] ""  Sub_Gateway
 SG_ MO_Anzahl_Abgesch_Zyl : 47|3@1+ (1,0) [0|7] ""  Sub_Gateway
 SG_ MO_Zylabsch_Texte : 50|2@1+ (1,0) [0|3] ""  Sub_Gateway
 SG_ MO_Ethanol_BS_Texte : 52|3@1+ (1,0) [0|7] ""  Sub_Gateway
 SG_ MO_Drehzahl_Warnung : 55|1@1+ (1,0) [0|1] ""  Sub_Gateway
 SG_ MO_obere_Drehzahlgrenze : 56|8@1+ (50,0) [50|12750] "Unit_MinutInver"  Sub_Gateway

BO_ 967 Motor_26: 8 Gateway
 SG_ MO_Kuehlerluefter_MUX M : 0|1@1+ (1,0) [0|1] ""  TME
 SG_ MO_Kuehlerluefter_1 m0 : 1|7@1+ (1,0) [0|100] "Unit_PerCent"  TME
 SG_ MO_Kuehlerluefter_2 m1 : 1|7@1+ (1,0) [0|100] "Unit_PerCent"  TME
 SG_ MO_EFLEX_Lampe : 8|2@1+ (1,0) [0|3] "" Vector__XXX
 SG_ MO_KJS_nicht_bereit : 10|1@1+ (1,0) [0|1] "" Vector__XXX
 SG_ MO_ITM_Warnung_Pumpe : 11|1@1+ (1,0) [0|1] "" Vector__XXX
 SG_ WIV_Anzeige_aktiv : 12|1@1+ (1,0) [0|1] "" Vector__XXX
 SG_ WIV_Oelmin_Warn : 13|1@1+ (1,0) [0|1] "" Vector__XXX
 SG_ WIV_Sensorfehler : 14|1@1+ (1,0) [0|1] "" Vector__XXX
 SG_ WIV_Schieflage : 15|1@1+ (1,0) [0|1] "" Vector__XXX
 SG_ WIV_Oelstand : 16|4@1+ (12.5,0) [0|100] "Unit_PerCent" Vector__XXX
 SG_ MO_Zustand_HWP : 20|2@1+ (1,0) [0|3] ""  TME
 SG_ OLEV_Systemstoerung : 22|1@1+ (1,0) [0|1] "" Vector__XXX
 SG_ MO_Oelwarnung_max : 23|1@1+ (1,0) [0|1] "" Vector__XXX
 SG_ WIV_Oelsystem_aktiv : 24|1@1+ (1,0) [0|1] "" Vector__XXX
 SG_ WIV_nicht_betriebswarm : 25|1@1+ (1,0) [0|1] "" Vector__XXX
 SG_ WIV_Ueberfuell_Warn : 26|1@1+ (1,0) [0|1] "" Vector__XXX
 SG_ WIV_laufender_Motor : 27|1@1+ (1,0) [0|1] "" Vector__XXX
 SG_ MO_E_Warnungen : 28|4@1+ (1,0) [0|15] "" Vector__XXX
 SG_ MO_Text_Motorstart : 32|4@1+ (1,0) [0|15] "" Vector__XXX
 SG_ MO_E_Texte : 36|4@1+ (1,0) [0|15] "" Vector__XXX
 SG_ WIV_Oeldyn_avl : 40|1@1+ (1,0) [0|1] "" Vector__XXX
 SG_ MO_Text_Partikelfil_Reg : 41|1@1+ (1,0) [0|1] "" Vector__XXX
 SG_ OLEV_Oelstand_nicht_vorhanden : 42|1@1+ (1,0) [0|1] "" Vector__XXX
 SG_ WIV_Oelmenge : 43|5@1+ (125,0) [0|3875] "Unit_MilliLiter" Vector__XXX
 SG_ MO_Systemlampe : 48|1@1+ (1,0) [0|1] "" Vector__XXX
 SG_ MO_OBD2_Lampe : 49|1@1+ (1,0) [0|1] "" Vector__XXX
 SG_ MO_Heissleuchte : 50|1@1+ (1,0) [0|1] ""  TME
 SG_ MO_Partikel_Lampe : 51|1@1+ (1,0) [0|1] "" Vector__XXX
 SG_ MO_RedFahrleistung_Lampe : 52|1@1+ (1,0) [0|1] "" Vector__XXX
 SG_ WIV_Oelstand_nicht_vorhanden : 53|1@1+ (1,0) [0|1] "" Vector__XXX
 SG_ WIV_nachfuellanzeige_ein : 54|1@1+ (1,0) [0|1] "" Vector__XXX
 SG_ WIV_Ueberfuell_deaktiv : 55|1@1+ (1,0) [0|1] "" Vector__XXX
 SG_ WIV_Unterfuell_Warn : 56|1@1+ (1,0) [0|1] "" Vector__XXX
 SG_ MO_Tankdeckel_Lampe : 57|1@1+ (1,0) [0|1] "" Vector__XXX
 SG_ MO_Text_Tankdeckelwarn : 58|1@1+ (1,0) [0|1] "" Vector__XXX
 SG_ MO_Vorglueh_Lampe : 59|1@1+ (1,0) [0|1] "" Vector__XXX
 SG_ WIV_Oeldr_Warn_Motor : 60|1@1+ (1,0) [0|1] "" Vector__XXX
 SG_ MO_E_Mode : 61|3@1+ (1,0) [0|7] "" Vector__XXX

BO_ 916 WBA_03: 8 Gateway
 SG_ WBA_03_CRC : 0|8@1+ (1,0) [0|255] ""  Sub_Gateway
 SG_ WBA_03_BZ : 8|4@1+ (1,0) [0|15] ""  Sub_Gateway
 SG_ WBA_Fahrstufe_02 : 12|4@1+ (1,0) [0|15] ""  Sub_Gateway
 SG_ WBA_ZielFahrstufe : 16|4@1+ (1,0) [0|15] ""  Sub_Gateway
 SG_ WBA_GE_Warnung_02 : 20|4@1+ (1,0) [0|15] ""  Sub_Gateway
 SG_ WBA_eing_Gang_02 : 24|4@1+ (1,0) [0|15] ""  Sub_Gateway
 SG_ WBA_GE_Texte : 28|3@1+ (1,0) [0|7] ""  Sub_Gateway
 SG_ WBA_Segeln_aktiv : 31|1@1+ (1,0) [0|1] ""  Sub_Gateway
 SG_ WBA_Schaltschema : 32|5@1+ (1,0) [0|31] ""  Sub_Gateway
 SG_ WBA_GE_Zusatzwarnungen : 37|3@1+ (1,0) [0|7] ""  Sub_Gateway
 SG_ GE_Sollgang : 40|4@1+ (1,0) [0|15] ""  Sub_Gateway
 SG_ GE_Tipschaltempf_verfuegbar : 44|1@1+ (1,0) [0|1] ""  Sub_Gateway
 SG_ WBA_GE_Texte_02 : 45|3@1+ (1,0) [0|7] ""  Sub_Gateway
 SG_ WBA_GE_Texte_03 : 48|4@1+ (1,0) [0|15] ""  Sub_Gateway
 SG_ WBA_Blinken : 54|1@1+ (1,0) [0|1] ""  Sub_Gateway
 SG_ GE_Wiederstart_Anz_Std : 55|1@1+ (1,0) [0|1] ""  Sub_Gateway
 SG_ GE_Stoppverbot_Anz_01 : 56|1@1+ (1,0) [0|1] ""  Sub_Gateway
 SG_ GE_Stoppverbot_Anz_02 : 57|1@1+ (1,0) [0|1] ""  Sub_Gateway
 SG_ GE_Stoppverbot_Anz_03 : 58|1@1+ (1,0) [0|1] ""  Sub_Gateway
 SG_ GE_Stoppverbot_Anz_04 : 59|1@1+ (1,0) [0|1] ""  Sub_Gateway
 SG_ GE_Stoppverbot_Anz_05 : 60|1@1+ (1,0) [0|1] ""  Sub_Gateway
 SG_ GE_Stoppverbot_Anz_06 : 61|1@1+ (1,0) [0|1] ""  Sub_Gateway
 SG_ GE_Stoppverbot_Anz_07 : 62|1@1+ (1,0) [0|1] ""  Sub_Gateway
 SG_ GE_Stoppverbot_Anz_Std : 63|1@1+ (1,0) [0|1] ""  Sub_Gateway

BO_ 1283 HVK_01: 8 Gateway
 SG_ HVK_01_CRC : 0|8@1+ (1,0) [0|255] ""  BMC_MLBevo,DCDC_800V_PAG,DCDC_HV,DCDC_HV_02,FCU_MLBevo_FCEV,Ladegeraet_2,Ladegeraet_Konzern,LE1,LE2,LE_MLBevo,TME
 SG_ HVK_01_BZ : 8|4@1+ (1,0) [0|15] ""  BMC_MLBevo,DCDC_800V_PAG,DCDC_HV,DCDC_HV_02,FCU_MLBevo_FCEV,Ladegeraet_2,Ladegeraet_Konzern,LE1,LE2,LE_MLBevo,TME
 SG_ HVK_Istmodus_Anf : 12|1@1+ (1,0) [0|1] ""  BMC_MLBevo,DCDC_HV,FCU_MLBevo_FCEV,Ladegeraet_2,Ladegeraet_Konzern,LE1,LE2,LE_MLBevo
 SG_ HVK_TN1_Sollmodus : 13|2@1+ (1,0) [0|3] ""  DCDC_HV_02,FCU_MLBevo_FCEV
 SG_ HVK_MO_EmSollzustand : 16|8@1+ (1,0) [0|255] ""  FCU_MLBevo_FCEV
 SG_ HVK_BMS_Sollmodus : 24|3@1+ (1,0) [0|7] ""  BMC_MLBevo,FCU_MLBevo_FCEV
 SG_ HVK_DCDC_Sollmodus : 27|3@1+ (1,0) [0|7] ""  DCDC_800V_PAG,DCDC_HV,FCU_MLBevo_FCEV,LE_MLBevo
 SG_ HVK_EKK_Sollmodus : 30|3@1+ (1,0) [0|7] ""  FCU_MLBevo_FCEV,TME
 SG_ HVK_HVPTC_Sollmodus : 33|3@1+ (1,0) [0|7] ""  FCU_MLBevo_FCEV,TME
 SG_ HVK_HVLM_Sollmodus : 36|3@1+ (1,0) [0|7] ""  DCDC_HV_02,FCU_MLBevo_FCEV,Ladegeraet_Konzern
 SG_ HVK_HV_Netz_Warnungen : 39|2@1+ (1,0) [0|3] ""  FCU_MLBevo_FCEV
 SG_ HV_Bordnetz_aktiv : 41|1@1+ (1,0) [0|1] ""  DCDC_HV_02,FCU_MLBevo_FCEV,Ladegeraet_Konzern,LE1,LE2,LE_MLBevo
 SG_ HV_Bordnetz_Fehler : 42|1@1+ (1,0) [0|1] ""  FCU_MLBevo_FCEV,Ladegeraet_Konzern,TME
 SG_ HVK_Gesamtst_Spgfreiheit : 43|2@1+ (1,0) [0|3] ""  FCU_MLBevo_FCEV
 SG_ HVK_AktiveEntladung_Anf : 45|1@1+ (1,0) [0|1] ""  DCDC_800V_PAG,DCDC_HV,DCDC_HV_02,FCU_MLBevo_FCEV,LE1,LE2,LE_MLBevo
 SG_ HVK_Iso_Messung_Start : 50|3@1+ (1,0) [0|7] ""  BMC_MLBevo,FCU_MLBevo_FCEV
 SG_ HVK_DCDC_EKK_Sollmodus : 62|2@1+ (1,0) [0|3] ""  DCDC_800V_PAG,FCU_MLBevo_FCEV

BO_ 949 Klima_11: 8 Gateway
 SG_ KL_Drehz_Anh : 0|1@1+ (1,0) [0|1] ""  TME
 SG_ KL_Vorwarn_Komp_ein : 1|1@1+ (1,0) [0|1] ""  TME
 SG_ KL_AC_Schalter : 2|1@1+ (1,0) [0|1] ""  TME
 SG_ KL_Komp_Moment_alt : 3|1@1+ (1,0) [0|1] ""  TME
 SG_ KL_Vorwarn_Zuheizer_ein : 6|1@1+ (1,0) [0|1] "" Vector__XXX
 SG_ KL_Zustand : 7|1@1+ (1,0) [0|1] ""  TME
 SG_ KL_Kompressorkupplung_linear : 8|8@1+ (20,0) [0|4000] "Unit_MilliAmper" Vector__XXX
 SG_ KL_Charisma_FahrPr : 16|4@1+ (1,0) [0|15] ""  TME
 SG_ KL_Charisma_Status : 20|2@1+ (1,0) [0|3] ""  TME
 SG_ KL_nachtr_Stopp_Anf : 22|1@1+ (1,0) [0|1] "" Vector__XXX
 SG_ KL_T_Charge : 23|1@1+ (1,0) [0|1] "" Vector__XXX
 SG_ KL_Last_Kompr : 24|8@1+ (0.25,0) [0|63.5] "Unit_NewtoMeter"  TME
 SG_ KL_Spannungs_Anf : 32|2@1+ (1,0) [0|3] "" Vector__XXX
 SG_ KL_Thermomanagement : 34|2@1+ (1,0) [0|3] ""  TME
 SG_ KL_StartStopp_Info : 36|2@1+ (1,0) [0|3] ""  TME
 SG_ KL_Freilauf_Info : 38|2@1+ (1,0) [0|3] "" Vector__XXX
 SG_ KL_Anf_KL : 40|8@1+ (0.4,0) [0|101.6] "Unit_PerCent"  TME
 SG_ KL_el_Zuheizer_Stufe : 48|3@1+ (1,0) [0|7] ""  TME
 SG_ KL_Ausstattung_Klima : 51|3@1+ (1,0) [0|7] "" Vector__XXX
 SG_ KL_Variante_Standheizung : 54|2@1+ (1,0) [0|3] "" Vector__XXX

BO_ 1640 Klima_12: 8 Gateway
 SG_ KL_LRH_Taster : 0|1@1+ (1,0) [0|1] "" Vector__XXX
 SG_ KL_LRH_Stufe : 1|2@1+ (1,0) [0|3] "" Vector__XXX
 SG_ HSH_Taster : 3|2@1+ (1,0) [0|3] "" Vector__XXX
 SG_ FSH_Taster : 5|1@1+ (1,0) [0|1] "" Vector__XXX
 SG_ KL_Zuheizer_Freigabe : 6|1@1+ (1,0) [0|1] ""  TME
 SG_ KL_Beschlagsgefahr : 7|1@1+ (1,0) [0|1] ""  TME
 SG_ KL_SIH_Soll_li : 8|3@1+ (1,0) [0|7] ""  TME
 SG_ KL_SIH_Soll_re : 11|3@1+ (1,0) [0|7] ""  TME
 SG_ KRH_Soll_li : 14|2@1+ (1,0) [0|3] "" Vector__XXX
 SG_ KL_SIL_Soll_li : 16|3@1+ (1,0) [0|7] ""  TME
 SG_ KL_SIL_Soll_re : 19|3@1+ (1,0) [0|7] ""  TME
 SG_ KRH_Soll_re : 22|2@1+ (1,0) [0|3] "" Vector__XXX
 SG_ KL_Geblspng_Soll : 24|8@1+ (0.05,1.45) [1.5|14] "Unit_Volt" Vector__XXX
 SG_ KL_Geblspng_Fond_Soll : 32|8@1+ (0.05,1.45) [1.5|14] "Unit_Volt" Vector__XXX
 SG_ KL_I_Geblaese : 40|8@1+ (0.25,0) [0|63.5] "Unit_Amper" Vector__XXX
 SG_ KL_Kompressorstrom_soll : 48|10@1+ (1,0) [0|1021] ""  TME
 SG_ KL_Umluftklappe_Status : 58|4@1+ (1,0) [0|15] ""  TME
 SG_ KL_PTC_Verbauinfo : 62|2@1+ (1,0) [0|3] "" Vector__XXX

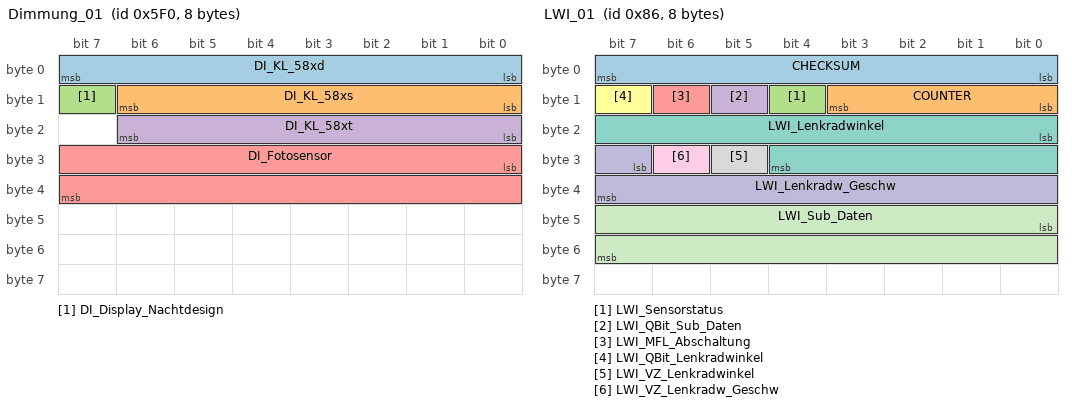
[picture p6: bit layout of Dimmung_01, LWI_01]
BO_ 1520 Dimmung_01: 8 Gateway_MQB
 SG_ DI_KL_58xd : 0|8@1+ (1,0) [0|253] "" Airbag_MQB
 SG_ DI_KL_58xs : 8|7@1+ (1,0) [0|100] "Unit_PerCent" Vector__XXX
 SG_ DI_Display_Nachtdesign : 15|1@1+ (1,0) [0|1] "" Vector__XXX
 SG_ DI_KL_58xt : 16|7@1+ (1,0) [0|100] "Unit_PerCent" Vector__XXX
 SG_ DI_Fotosensor : 24|16@1+ (1,0) [0|65535] "" Vector__XXX

BO_ 870 Blinkmodi_02: 8 Gateway
 SG_ BM_ZV_auf : 12|1@1+ (1.0,0.0) [0.0|1] ""  ZR_High
 SG_ BM_ZV_zu : 13|1@1+ (1.0,0.0) [0.0|1] ""  ZR_High
 SG_ BM_DWA_ein : 14|1@1+ (1.0,0.0) [0.0|1] ""  ZR_High
 SG_ BM_DWA_Alarm : 15|1@1+ (1.0,0.0) [0.0|1] ""  ZR_High
 SG_ BM_Crash : 16|1@1+ (1.0,0.0) [0.0|1] ""  ZR_High
 SG_ BM_Panik : 17|1@1+ (1.0,0.0) [0.0|1] ""  ZR_High
 SG_ BM_Not_Bremsung : 18|1@1+ (1.0,0.0) [0.0|1] ""  ZR_High
 SG_ BM_GDO : 19|1@1+ (1.0,0.0) [0.0|1] ""  Vector__XXX
 SG_ BM_Warnblinken : 20|1@1+ (1.0,0.0) [0.0|1] ""  ZR_High
 SG_ BM_Taxi_Notalarm : 21|1@1+ (1.0,0.0) [0.0|1] ""  ZR_High
 SG_ BM_Telematik : 22|1@1+ (1.0,0.0) [0.0|1] ""  ZR_High
 SG_ BM_links : 23|1@1+ (1.0,0.0) [0.0|1] ""  ZR_High
 SG_ BM_rechts : 24|1@1+ (1.0,0.0) [0.0|1] ""  ZR_High
 SG_ Blinken_li_Fzg_Takt : 25|1@1+ (1.0,0.0) [0.0|1] ""  ZR_High
 SG_ Blinken_re_Fzg_Takt : 26|1@1+ (1.0,0.0) [0.0|1] ""  ZR_High
 SG_ Blinken_li_Kombi_Takt : 27|1@1+ (1.0,0.0) [0.0|1] ""  ZR_High,ZR_LIMU,ZR_MIB_TOP_ab_Gen3,ZR_Standard
 SG_ Blinken_re_Kombi_Takt : 28|1@1+ (1.0,0.0) [0.0|1] ""  ZR_High,ZR_LIMU,ZR_MIB_TOP_ab_Gen3,ZR_Standard
 SG_ BM_NBA_n_codiert_n_aktiv : 29|1@1+ (1.0,0.0) [0.0|1] ""  Vector__XXX
 SG_ BM_NBA_Status : 30|2@1+ (1.0,0.0) [0.0|3] ""  Vector__XXX
 SG_ BM_WBT_Beleuchtung : 32|1@1+ (1.0,0.0) [0.0|1] ""  ZR_High
 SG_ BM_HD_Oeffnung_angelernt : 33|1@1+ (1.0,0.0) [0.0|1] ""  Vector__XXX
 SG_ BM_Autobahn : 34|1@1+ (1.0,0.0) [0.0|1] ""  ZR_High,ZR_LIMU,ZR_MIB_TOP_ab_Gen3
 SG_ BM_Rollenmodus_Blinken : 35|1@1+ (1.0,0.0) [0.0|1] ""  Vector__XXX
 SG_ BM_Recas : 36|1@1+ (1.0,0.0) [0.0|1] ""  ZR_High
 SG_ BM_Wischblinken : 37|1@1+ (1.0,0.0) [0.0|1] ""  ZR_High
 SG_ BM_Telematik_Abbruchgrund : 38|6@1+ (1.0,0.0) [0.0|63] ""  Vector__XXX
 SG_ BM_PiloPa : 44|1@1+ (1.0,0.0) [0.0|1] ""  ZR_High
 SG_ DWA_Alarmquelle : 59|5@1+ (1.0,0.0) [0.0|31] ""  ZR_High

BO_ 982 Licht_hinten_01: 8 Gateway_MQB
 SG_ Licht_hinten_01_BZ : 0|4@1+ (1,0) [0|15] "" Motor_Diesel_MQB,Motor_Hybrid_MQB,Motor_Otto_MQB
 SG_ BCM2_Bremsl_durch_ECD : 5|1@1+ (1,0) [0|1] "" Motor_Diesel_MQB,Motor_Hybrid_MQB,Motor_Otto_MQB
 SG_ LH_Aussenlicht_def : 7|1@1+ (1,0) [0|1] "" Vector__XXX
 SG_ LH_Standlicht_H_aktiv : 8|1@1+ (1,0) [0|1] "" Vector__XXX
 SG_ LH_Parklicht_HL_aktiv : 9|1@1+ (1,0) [0|1] "" Vector__XXX
 SG_ LH_Parklicht_HR_aktiv : 10|1@1+ (1,0) [0|1] "" Vector__XXX
 SG_ LH_Bremslicht_H_aktiv : 11|1@1+ (1,0) [0|1] "" Vector__XXX
 SG_ LH_Nebelschluss_aktiv : 12|1@1+ (1,0) [0|1] "" Vector__XXX
 SG_ LH_Rueckfahrlicht_aktiv : 13|1@1+ (1,0) [0|1] "" Vector__XXX
 SG_ LH_Blinker_HL_akt : 14|1@1+ (1,0) [0|1] "" Vector__XXX
 SG_ LH_Blinker_HR_akt : 15|1@1+ (1,0) [0|1] "" Vector__XXX
 SG_ LH_Blinker_li_def : 16|1@1+ (1,0) [0|1] "" Vector__XXX
 SG_ LH_Bremsl_li_def : 17|1@1+ (1,0) [0|1] "" Vector__XXX
 SG_ LH_Schlusslicht_li_def : 18|1@1+ (1,0) [0|1] "" Vector__XXX
 SG_ LH_Rueckf_li_def : 19|1@1+ (1,0) [0|1] "" Vector__XXX
 SG_ LH_Nebel_li_def : 20|1@1+ (1,0) [0|1] "" Vector__XXX
 SG_ LH_Schluss_Brems_Nebel_li_def : 21|1@1+ (1,0) [0|1] "" Vector__XXX
 SG_ LH_Schluss_Brems_Nebel_re_def : 22|1@1+ (1,0) [0|1] "" Vector__XXX
 SG_ LH_Schluss_Brems_li_def : 24|1@1+ (1,0) [0|1] "" Vector__XXX
 SG_ LH_Schluss_Nebel_li_def : 25|1@1+ (1,0) [0|1] "" Vector__XXX
 SG_ LH_SL_BRL_BLK_li_def : 26|1@1+ (1,0) [0|1] "" Vector__XXX
 SG_ LH_Brems_Blk_li_def : 27|1@1+ (1,0) [0|1] "" Vector__XXX
 SG_ LH_Blinker_re_def : 32|1@1+ (1,0) [0|1] "" Vector__XXX
 SG_ LH_Bremsl_re_def : 33|1@1+ (1,0) [0|1] "" Vector__XXX
 SG_ LH_Schlusslicht_re_def : 34|1@1+ (1,0) [0|1] "" Vector__XXX
 SG_ LH_Rueckf_re_def : 35|1@1+ (1,0) [0|1] "" Vector__XXX
 SG_ LH_Nebel_re_def : 36|1@1+ (1,0) [0|1] "" Vector__XXX
 SG_ LH_Schluss_Brems_re_def : 40|1@1+ (1,0) [0|1] "" Vector__XXX
 SG_ LH_Schluss_Nebel_re_def : 41|1@1+ (1,0) [0|1] "" Vector__XXX
 SG_ LH_SL_BRL_BLK_re_def : 42|1@1+ (1,0) [0|1] "" Vector__XXX
 SG_ LH_Brems_Blk_re_def : 43|1@1+ (1,0) [0|1] "" Vector__XXX
 SG_ LH_Kennzl_def : 48|1@1+ (1,0) [0|1] "" Vector__XXX
 SG_ LH_3_Bremsl_def : 49|1@1+ (1,0) [0|1] "" Motor_Diesel_MQB,Motor_Hybrid_MQB,Motor_Otto_MQB
 SG_ LH_Nebel_mi_def : 50|1@1+ (1,0) [0|1] "" Vector__XXX
 SG_ LH_Rueckf_mi_def : 51|1@1+ (1,0) [0|1] "" Vector__XXX
 SG_ LH_Bremsl_li_ges_def : 54|1@1+ (1,0) [0|1] "" Motor_Diesel_MQB,Motor_Hybrid_MQB,Motor_Otto_MQB
 SG_ LH_Bremsl_re_ges_def : 55|1@1+ (1,0) [0|1] "" Motor_Diesel_MQB,Motor_Hybrid_MQB,Motor_Otto_MQB

BO_ 987 Gateway_72: 8 Gateway_MQB
 SG_ BCM_01_alt : 0|1@1+ (1,0) [0|1] "" Airbag_MQB
 SG_ SMLS_01_alt : 1|1@1+ (1,0) [0|1] "" Motor_Diesel_MQB,Motor_Otto_MQB
 SG_ ZV_02_alt : 2|1@1+ (1,0) [0|1] "" Getriebe_DQ_Hybrid_MQB,Getriebe_DQ_MQB,Motor_Diesel_MQB,Motor_Hybrid_MQB,Motor_Otto_MQB
 SG_ Wischer_01_alt : 3|1@1+ (1,0) [0|1] "" Motor_Diesel_MQB,Motor_Hybrid_MQB,Motor_Otto_MQB
 SG_ Anhaenger_01_alt : 4|1@1+ (1,0) [0|1] "" Getriebe_DQ_Hybrid_MQB,Getriebe_DQ_MQB
 SG_ Klima_Sensor_02_alt : 5|1@1+ (1,0) [0|1] "" Getriebe_DQ_Hybrid_MQB,Getriebe_DQ_MQB,Motor_Diesel_MQB,Motor_Hybrid_MQB,Motor_Otto_MQB
 SG_ VSG_01_alt : 6|1@1+ (1,0) [0|1] "" Airbag_MQB
 SG_ Klima_01_alt : 7|1@1+ (1,0) [0|1] "" Vector__XXX
 SG_ WFS_01_alt : 8|1@1+ (1,0) [0|1] "" Vector__XXX
 SG_ Licht_Anf_01_alt : 9|1@1+ (1,0) [0|1] "" Vector__XXX
 SG_ ZV_HFS_offen : 20|1@1+ (1,0) [0|1] "" Vector__XXX
 SG_ ZV_HBFS_offen : 21|1@1+ (1,0) [0|1] "" Vector__XXX
 SG_ VS_VD_offen_ver : 22|1@1+ (1,0) [0|1] "" Airbag_MQB
 SG_ VS_VD_zu_ver : 23|1@1+ (1,0) [0|1] "" Vector__XXX
 SG_ ZV_BT_offen : 24|1@1+ (1,0) [0|1] "" Vector__XXX
 SG_ BCM1_Rueckfahrlicht_Schalter : 25|1@1+ (1,0) [0|1] "" Airbag_MQB
 SG_ ZV_FT_offen : 26|1@1+ (1,0) [0|1] "" Getriebe_DQ_Hybrid_MQB,Getriebe_DQ_MQB,Motor_Diesel_MQB,Motor_Hybrid_MQB,Motor_Otto_MQB
 SG_ Wischer_vorne_aktiv : 27|1@1+ (1,0) [0|1] "" Motor_Diesel_MQB,Motor_Hybrid_MQB,Motor_Otto_MQB
 SG_ AAG_Anhaenger_erkannt : 28|1@1+ (1,0) [0|1] "" Getriebe_DQ_Hybrid_MQB,Getriebe_DQ_MQB
 SG_ BCM1_MH_Schalter : 29|1@1+ (1,0) [0|1] "" Vector__XXX
 SG_ ZV_HD_offen : 30|1@1+ (1,0) [0|1] "" Vector__XXX
 SG_ Waschen_vorne_aktiv : 31|1@1+ (1,0) [0|1] "" Vector__XXX
 SG_ KL_Thermomanagement : 32|2@1+ (1,0) [0|3] "" Vector__XXX
 SG_ WFS_Schluessel_Fahrberecht : 34|4@1+ (1,0) [0|15] "" Vector__XXX
 SG_ BCM1_RFahrlicht_Fzg_Anf : 38|1@1+ (1,0) [0|1] "" Vector__XXX
 SG_ BCM1_RFahrlicht_Ahg_Anf : 39|1@1+ (1,0) [0|1] "" Vector__XXX
 SG_ BH_Fernlicht : 49|1@1+ (1,0) [0|1] "" Vector__XXX
 SG_ BH_Blinker_li : 50|1@1+ (1,0) [0|1] "" Motor_Diesel_MQB,Motor_Otto_MQB
 SG_ BH_Blinker_re : 51|1@1+ (1,0) [0|1] "" Motor_Diesel_MQB,Motor_Otto_MQB
 SG_ BCM1_OBD_FStatus_ATemp : 52|4@1+ (1,0) [0|15] "" Getriebe_DQ_Hybrid_MQB,Getriebe_DQ_MQB,Motor_Diesel_MQB,Motor_Hybrid_MQB,Motor_Otto_MQB
 SG_ BCM1_Aussen_Temp_ungef : 56|8@1+ (0.5,-50) [-50|76] "Unit_DegreCelsi" Getriebe_DQ_Hybrid_MQB,Getriebe_DQ_MQB,Motor_Diesel_MQB,Motor_Hybrid_MQB,Motor_Otto_MQB

BO_ 299 GRA_ACC_01: 8 Gateway
 SG_ CHECKSUM : 0|8@1+ (1,0) [0|255] ""  Vector__XXX
 SG_ COUNTER : 8|4@1+ (1,0) [0|15] ""  Vector__XXX
 SG_ GRA_Hauptschalter : 12|1@1+ (1.0,0.0) [0.0|1] ""  ZR_High
 SG_ GRA_Abbrechen : 13|1@1+ (1.0,0.0) [0.0|1] ""  ZR_High
 SG_ GRA_Typ_Hauptschalter : 14|1@1+ (1.0,0.0) [0.0|1] ""  ZR_High
 SG_ GRA_Limiter : 15|1@1+ (1.0,0.0) [0.0|1] ""  ZR_High
 SG_ GRA_Tip_Setzen : 16|1@1+ (1.0,0.0) [0.0|1] ""  ZR_High
 SG_ GRA_Tip_Hoch : 17|1@1+ (1.0,0.0) [0.0|1] ""  ZR_High
 SG_ GRA_Tip_Runter : 18|1@1+ (1.0,0.0) [0.0|1] ""  ZR_High
 SG_ GRA_Tip_Wiederaufnahme : 19|1@1+ (1.0,0.0) [0.0|1] ""  ZR_High
 SG_ GRA_Verstellung_Zeitluecke : 20|2@1+ (1.0,0.0) [0.0|3] ""  ZR_High
 SG_ GRA_Codierung : 22|2@1+ (1.0,0.0) [0.0|3] ""  ZR_High
 SG_ GRA_Fehler : 24|1@1+ (1.0,0.0) [0.0|1] ""  ZR_High
 SG_ GRA_LIM_Taste_verfuegbar : 25|1@1+ (1.0,0.0) [0.0|1] ""  ZR_High
 SG_ GRA_Tip_Stufe_2 : 26|1@1+ (1.0,0.0) [0.0|1] ""  ZR_High
 SG_ GRA_ButtonTypeInfo : 27|3@1+ (1.0,0.0) [0.0|7] ""  ZR_High
 SG_ GRA_TravelAssist : 30|1@1+ (1.0,0.0) [0.0|1] ""  Vector__XXX
 SG_ GRA_reserveByte4 : 31|1@1+ (1.0,0.0) [0.0|1] ""  Vector__XXX
 SG_ GRA_reserveByte5 : 32|8@1+ (1.0,0.0) [0.0|255] ""  Vector__XXX
 SG_ GRA_reserveByte6 : 40|8@1+ (1.0,0.0) [0.0|255] ""  Vector__XXX
 SG_ GRA_reserveByte7 : 48|8@1+ (1.0,0.0) [0.0|255] ""  Vector__XXX
 SG_ GRA_reserveByte8 : 56|8@1+ (1.0,0.0) [0.0|255] ""  Vector__XXX

BO_ 134 LWI_01: 8 Gateway
 SG_ CHECKSUM : 0|8@1+ (1,0) [0|255] ""  Vector__XXX
 SG_ COUNTER : 8|4@1+ (1,0) [0|15] ""  Vector__XXX
 SG_ LWI_Sensorstatus : 12|1@1+ (1.0,0.0) [0.0|1] ""  ZR_High,ZR_LIMU,ZR_MIB_TOP_ab_Gen3,ZR_Standard
 SG_ LWI_QBit_Sub_Daten : 13|1@1+ (1.0,0.0) [0.0|1] ""  ZR_High
 SG_ LWI_MFL_Abschaltung : 14|1@1+ (1.0,0.0) [0.0|1] ""  ZR_High
 SG_ LWI_QBit_Lenkradwinkel : 15|1@1+ (1.0,0.0) [0.0|1] ""  ZR_High,ZR_LIMU,ZR_MIB_TOP_ab_Gen3,ZR_Standard
 SG_ LWI_Lenkradwinkel : 16|13@1+ (0.1,0) [0.0|800.0] "Unit_DegreOfArc"  OTA_FC,ZR_High,ZR_LIMU,ZR_MIB_TOP_ab_Gen3,ZR_Standard
 SG_ LWI_VZ_Lenkradwinkel : 29|1@1+ (1.0,0.0) [0.0|1] ""  OTA_FC,ZR_High,ZR_LIMU,ZR_MIB_TOP_ab_Gen3,ZR_Standard
 SG_ LWI_VZ_Lenkradw_Geschw : 30|1@1+ (1.0,0.0) [0.0|1] ""  ZR_High
 SG_ LWI_Lenkradw_Geschw : 31|9@1+ (5,0) [0|2500] "Unit_DegreOfArcPerSecon"  OTA_FC,ZR_High
 SG_ LWI_Sub_Daten : 40|16@1+ (1,0) [0|65535] ""  Vector__XXX

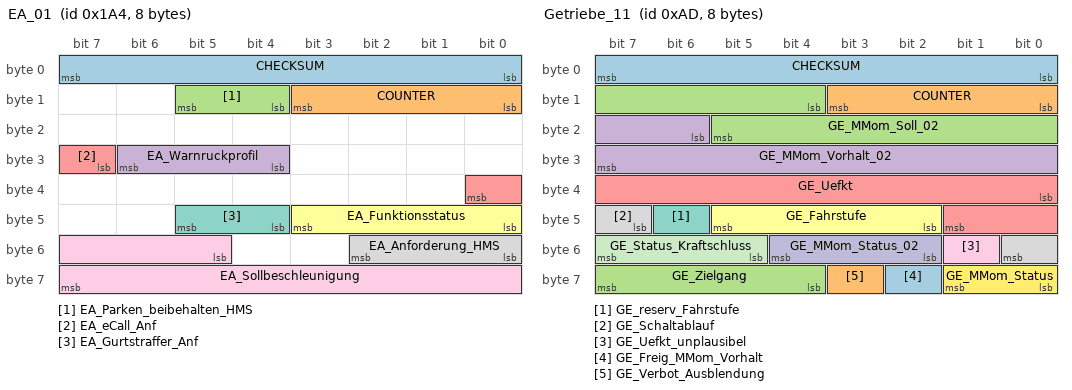
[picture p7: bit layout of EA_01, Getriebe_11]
BO_ 420 EA_01: 8 Gateway
 SG_ CHECKSUM : 0|8@1+ (1,0) [0|255] ""  Vector__XXX
 SG_ COUNTER : 8|4@1+ (1,0) [0|15] ""  Vector__XXX
 SG_ EA_Parken_beibehalten_HMS : 12|2@1+ (1.0,0.0) [0.0|3] ""  Vector__XXX
 SG_ EA_Warnruckprofil : 28|3@1+ (1.0,0.0) [0.0|7] ""  Vector__XXX
 SG_ EA_eCall_Anf : 31|2@1+ (1.0,0.0) [0.0|3] ""  ZR_High
 SG_ EA_Funktionsstatus : 40|4@1+ (1.0,0.0) [0.0|15] ""  ZR_High
 SG_ EA_Gurtstraffer_Anf : 44|2@1+ (1.0,0.0) [0.0|3] ""  Vector__XXX
 SG_ EA_Anforderung_HMS : 48|3@1+ (1.0,0.0) [0.0|7] ""  Vector__XXX
 SG_ EA_Sollbeschleunigung : 53|11@1+ (0.005,-7.22) [-7.220|3.005] "Unit_MeterPerSeconSquar"  Vector__XXX

BO_ 695 RCTA_01: 8 XXX
 SG_ RCTA_01_BZ : 8|4@1+ (1,0) [0|15] "" XXX
 SG_ RCTA_01_CRC : 0|8@1+ (1,0) [0|255] "" XXX

BO_ 173 Getriebe_11: 8 Gateway
 SG_ CHECKSUM : 0|8@1+ (1,0) [0|255] ""  Vector__XXX
 SG_ COUNTER : 8|4@1+ (1,0) [0|15] ""  Vector__XXX
 SG_ GE_MMom_Soll_02 : 12|10@1+ (1,-509) [-509|509] ""  Vector__XXX
 SG_ GE_MMom_Vorhalt_02 : 22|10@1+ (1,-509) [-509|509] ""  Vector__XXX
 SG_ GE_Uefkt : 32|10@1+ (0.1,0) [0.0|102.2] ""  Vector__XXX
 SG_ GE_Fahrstufe : 42|4@1+ (1.0,0.0) [0.0|15] ""  DDA,OTA_FC,ZR_High,ZR_LIMU,ZR_MIB_TOP_ab_Gen3
 SG_ GE_reserv_Fahrstufe : 46|1@1+ (1,0) [0|1] ""  Vector__XXX
 SG_ GE_Schaltablauf : 47|2@1+ (1.0,0.0) [0.0|3] ""  Vector__XXX
 SG_ GE_Uefkt_unplausibel : 49|1@1+ (1.0,0.0) [0.0|1] ""  Vector__XXX
 SG_ GE_MMom_Status_02 : 50|3@1+ (1.0,0.0) [0.0|7] ""  Vector__XXX
 SG_ GE_Status_Kraftschluss : 53|3@1+ (1.0,0.0) [0.0|7] ""  Vector__XXX
 SG_ GE_MMom_Status : 56|2@1+ (1.0,0.0) [0.0|3] ""  Vector__XXX
 SG_ GE_Freig_MMom_Vorhalt : 58|1@1+ (1.0,0.0) [0.0|1] ""  Vector__XXX
 SG_ GE_Verbot_Ausblendung : 59|1@1+ (1.0,0.0) [0.0|1] ""  Vector__XXX
 SG_ GE_Zielgang : 60|4@1+ (1.0,0.0) [0.0|15] ""  OTA_FC,ZR_High

BO_ 1411 ZV_02: 8 Gateway
 SG_ BCM_FH_Freigabe : 12|1@1+ (1.0,0.0) [0.0|1] ""  BedienDisp_vo
 SG_ BCM_Komfortfkt_Freigabe : 13|1@1+ (1.0,0.0) [0.0|1] ""  Vector__XXX
 SG_ BCM_HSK_Freigabe : 14|1@1+ (1.0,0.0) [0.0|1] ""  Vector__XXX
 SG_ BCM_Verdeck_Freigabe : 15|1@1+ (1.0,0.0) [0.0|1] ""  ZR_High
 SG_ ZV_verriegelt_intern_ist : 16|1@1+ (1.0,0.0) [0.0|1] ""  DDA,OTA_FC,ZR_High
 SG_ ZV_verriegelt_extern_ist : 17|1@1+ (1.0,0.0) [0.0|1] ""  DDA,OTA_FC,ZR_High
 SG_ ZV_verriegelt_intern_soll : 18|1@1+ (1.0,0.0) [0.0|1] ""  ZR_High
 SG_ ZV_verriegelt_extern_soll : 19|1@1+ (1.0,0.0) [0.0|1] ""  OTA_FC,ZR_High,ZR_LIMU,ZR_MIB_TOP_ab_Gen3,ZR_Standard
 SG_ ZV_gesafet_extern_ist : 20|1@1+ (1.0,0.0) [0.0|1] ""  ZR_High
 SG_ ZV_gesafet_extern_soll : 21|1@1+ (1.0,0.0) [0.0|1] ""  ZR_High,ZR_LIMU,ZR_MIB_TOP_ab_Gen3
 SG_ ZV_Einzeltuerentriegelung : 22|1@1+ (1.0,0.0) [0.0|1] ""  Vector__XXX
 SG_ ZV_Heckeinzelentriegelung : 23|1@1+ (1.0,0.0) [0.0|1] ""  Vector__XXX
 SG_ ZV_FT_offen : 24|1@1+ (1.0,0.0) [0.0|1] ""  DDA,OTA_FC,ZR_High,ZR_LIMU,ZR_MIB_TOP_ab_Gen3,ZR_Standard
 SG_ ZV_BT_offen : 25|1@1+ (1.0,0.0) [0.0|1] ""  DDA,OTA_FC,ZR_High,ZR_LIMU,ZR_MIB_TOP_ab_Gen3,ZR_Standard
 SG_ ZV_HFS_offen : 26|1@1+ (1.0,0.0) [0.0|1] ""  DDA,OTA_FC,ZR_High,ZR_LIMU,ZR_MIB_TOP_ab_Gen3,ZR_Standard
 SG_ ZV_HBFS_offen : 27|1@1+ (1.0,0.0) [0.0|1] ""  DDA,OTA_FC,ZR_High,ZR_LIMU,ZR_MIB_TOP_ab_Gen3,ZR_Standard
 SG_ ZV_HD_offen : 28|1@1+ (1.0,0.0) [0.0|1] ""  DDA,OTA_FC,ZR_High,ZR_LIMU,ZR_MIB_TOP_ab_Gen3,ZR_Standard
 SG_ ZV_HS_offen : 29|1@1+ (1.0,0.0) [0.0|1] ""  OTA_FC,ZR_High
 SG_ IRUE_aktiv : 30|1@1+ (1.0,0.0) [0.0|1] ""  ZR_High
 SG_ DWA_aktiv : 31|1@1+ (1.0,0.0) [0.0|1] ""  ZR_High
 SG_ HD_Hauptraste : 32|1@1+ (1.0,0.0) [0.0|1] ""  OTA_FC,ZR_High
 SG_ HD_Vorraste : 33|1@1+ (1.0,0.0) [0.0|1] ""  OTA_FC,ZR_High
 SG_ FFB_CarFinder : 38|1@1+ (1.0,0.0) [0.0|1] ""  Vector__XXX
 SG_ FFB_Komfortoeffnen : 39|1@1+ (1.0,0.0) [0.0|1] ""  Vector__XXX
 SG_ FFB_Komfortschliessen : 40|1@1+ (1.0,0.0) [0.0|1] ""  Vector__XXX
 SG_ ZV_Schluessel_Zugang : 42|4@1+ (1.0,0.0) [0.0|15] ""  ZR_High
 SG_ ZV_SafeFunktion_aktiv : 46|1@1+ (1.0,0.0) [0.0|1] ""  ZR_High
 SG_ FBS_Warn_Schluessel_Batt : 47|1@1+ (1.0,0.0) [0.0|1] ""  ZR_High
 SG_ ZV_Oeffnungsmodus : 48|2@1+ (1.0,0.0) [0.0|3] ""  Vector__XXX
 SG_ HFS_verriegelt : 50|1@1+ (1.0,0.0) [0.0|1] ""  OTA_FC
 SG_ HFS_gesafet : 51|1@1+ (1.0,0.0) [0.0|1] ""  Vector__XXX
 SG_ HBFS_verriegelt : 52|1@1+ (1.0,0.0) [0.0|1] ""  OTA_FC
 SG_ HBFS_gesafet : 53|1@1+ (1.0,0.0) [0.0|1] ""  Vector__XXX
 SG_ ZV_ist_Zustand_verfuegbar : 54|1@1+ (1.0,0.0) [0.0|1] ""  OTA_FC,ZR_High
 SG_ IRUE_Taster_Fkts_LED : 55|1@1+ (1.0,0.0) [0.0|1] ""  ZR_High
 SG_ ZV_Tankklappe_offen : 56|1@1+ (1.0,0.0) [0.0|1] ""  ZR_High
 SG_ ZV_Rollo_auf : 57|1@1+ (1.0,0.0) [0.0|1] ""  ZR_High
 SG_ ZV_Rollo_zu : 58|1@1+ (1.0,0.0) [0.0|1] ""  ZR_High
 SG_ ZV_SAD_auf : 59|1@1+ (1.0,0.0) [0.0|1] ""  ZR_High
 SG_ ZV_SAD_zu : 60|1@1+ (1.0,0.0) [0.0|1] ""  ZR_High
 SG_ BCM_Tankklappensteller_Fehler : 61|1@1+ (1.0,0.0) [0.0|1] ""  ZR_High
 SG_ ZV_verriegelt_soll : 62|2@1+ (1.0,0.0) [0.0|3] ""  Vector__XXX

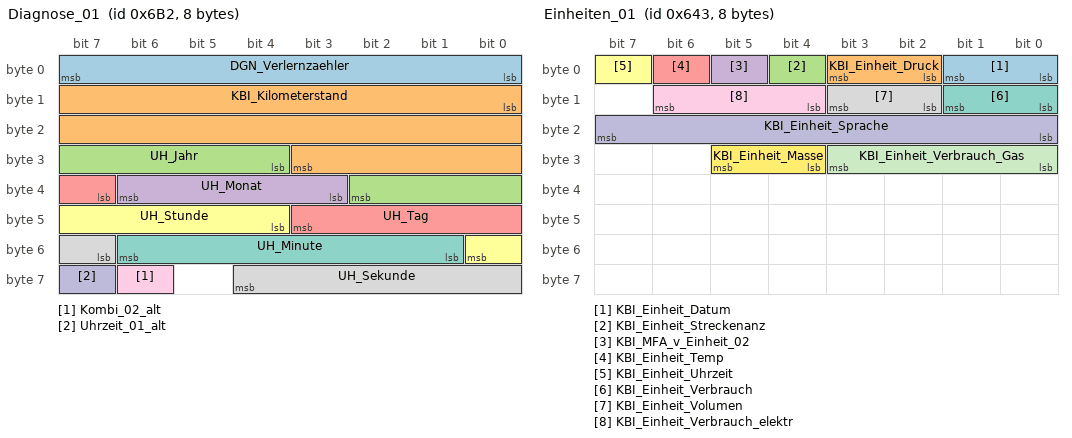
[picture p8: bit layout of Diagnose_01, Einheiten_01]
BO_ 1714 Diagnose_01: 8 Gateway_MQB
 SG_ DGN_Verlernzaehler : 0|8@1+ (1,0) [0|254] "" Airbag_MQB,BMS_MQB,Getriebe_DQ_Hybrid_MQB,Getriebe_DQ_MQB,LEH_MQB,SAK_MQB
 SG_ KBI_Kilometerstand : 8|20@1+ (1,0) [0|1048573] "Unit_KiloMeter" Airbag_MQB,BMS_MQB,Getriebe_DQ_Hybrid_MQB,Getriebe_DQ_MQB,LEH_MQB,Motor_Diesel_MQB,Motor_Hybrid_MQB,Motor_Otto_MQB,SAK_MQB
 SG_ UH_Jahr : 28|7@1+ (1,2000) [2000|2127] "Unit_Year" Airbag_MQB,BMS_MQB,Getriebe_DQ_Hybrid_MQB,Getriebe_DQ_MQB,LEH_MQB,Motor_Diesel_MQB,Motor_Hybrid_MQB,Motor_Otto_MQB,SAK_MQB
 SG_ UH_Monat : 35|4@1+ (1,0) [1|12] "Unit_Month" Airbag_MQB,BMS_MQB,Getriebe_DQ_Hybrid_MQB,Getriebe_DQ_MQB,LEH_MQB,Motor_Diesel_MQB,Motor_Hybrid_MQB,Motor_Otto_MQB,SAK_MQB
 SG_ UH_Tag : 39|5@1+ (1,0) [1|31] "Unit_Day" Airbag_MQB,BMS_MQB,Getriebe_DQ_Hybrid_MQB,Getriebe_DQ_MQB,LEH_MQB,Motor_Diesel_MQB,Motor_Hybrid_MQB,Motor_Otto_MQB,SAK_MQB
 SG_ UH_Stunde : 44|5@1+ (1,0) [0|23] "Unit_Hours" Airbag_MQB,BMS_MQB,Getriebe_DQ_Hybrid_MQB,Getriebe_DQ_MQB,LEH_MQB,Motor_Diesel_MQB,Motor_Hybrid_MQB,Motor_Otto_MQB,SAK_MQB
 SG_ UH_Minute : 49|6@1+ (1,0) [0|59] "Unit_Minut" Airbag_MQB,BMS_MQB,Getriebe_DQ_Hybrid_MQB,Getriebe_DQ_MQB,LEH_MQB,Motor_Diesel_MQB,Motor_Hybrid_MQB,Motor_Otto_MQB,SAK_MQB
 SG_ UH_Sekunde : 55|6@1+ (1,0) [0|59] "Unit_Secon" Airbag_MQB,BMS_MQB,Getriebe_DQ_Hybrid_MQB,Getriebe_DQ_MQB,LEH_MQB,Motor_Diesel_MQB,Motor_Hybrid_MQB,Motor_Otto_MQB,SAK_MQB
 SG_ Kombi_02_alt : 62|1@1+ (1,0) [0|1] "" Airbag_MQB,BMS_MQB,LEH_MQB
 SG_ Uhrzeit_01_alt : 63|1@1+ (1,0) [0|1] "" Airbag_MQB,BMS_MQB,LEH_MQB

BO_ 1716 VIN_01: 8 Gateway_MQB
 SG_ VIN_01_MUX M : 0|2@1+ (1,0) [0|3] ""  Airbag_MQB
 SG_ KS_Geheimnis_1 m0 : 8|8@1+ (1,0) [0|255] "" Vector__XXX
 SG_ VIN_4 m1 : 8|8@1+ (1,0) [0|255] ""  Airbag_MQB
 SG_ VIN_11 m2 : 8|8@1+ (1,0) [0|255] ""  Airbag_MQB
 SG_ KS_Geheimnis_2 m0 : 16|8@1+ (1,0) [0|255] "" Vector__XXX
 SG_ VIN_5 m1 : 16|8@1+ (1,0) [0|255] ""  Airbag_MQB
 SG_ VIN_12 m2 : 16|8@1+ (1,0) [0|255] ""  Airbag_MQB
 SG_ KS_Geheimnis_3 m0 : 24|8@1+ (1,0) [0|255] "" Vector__XXX
 SG_ VIN_6 m1 : 24|8@1+ (1,0) [0|255] ""  Airbag_MQB
 SG_ VIN_13 m2 : 24|8@1+ (1,0) [0|255] ""  Airbag_MQB
 SG_ KS_Geheimnis_4 m0 : 32|8@1+ (1,0) [0|255] "" Vector__XXX
 SG_ VIN_7 m1 : 32|8@1+ (1,0) [0|255] ""  Airbag_MQB
 SG_ VIN_14 m2 : 32|8@1+ (1,0) [0|255] ""  Airbag_MQB
 SG_ VIN_1 m0 : 40|8@1+ (1,0) [0|255] ""  Airbag_MQB
 SG_ VIN_8 m1 : 40|8@1+ (1,0) [0|255] ""  Airbag_MQB
 SG_ VIN_15 m2 : 40|8@1+ (1,0) [0|255] ""  Airbag_MQB
 SG_ VIN_2 m0 : 48|8@1+ (1,0) [0|255] ""  Airbag_MQB
 SG_ VIN_9 m1 : 48|8@1+ (1,0) [0|255] ""  Airbag_MQB
 SG_ VIN_16 m2 : 48|8@1+ (1,0) [0|255] ""  Airbag_MQB
 SG_ VIN_3 m0 : 56|8@1+ (1,0) [0|255] ""  Airbag_MQB
 SG_ VIN_10 m1 : 56|8@1+ (1,0) [0|255] ""  Airbag_MQB
 SG_ VIN_17 m2 : 56|8@1+ (1,0) [0|255] ""  Airbag_MQB

BO_ 974 TSG_HFS_01: 8 Gateway
 SG_ HFS_Tuer_geoeffnet : 0|1@1+ (1,0) [0|1] "" Vector__XXX
 SG_ HFS_verriegelt : 1|1@1+ (1,0) [0|1] "" Vector__XXX
 SG_ HFS_gesafet : 2|1@1+ (1,0) [0|1] "" Vector__XXX
 SG_ HFS_Heckrollotaster_betaetigt : 3|1@1+ (1,0) [0|1] "" Vector__XXX
 SG_ HFS_Tuerschloss_defekt : 4|1@1+ (1,0) [0|1] "" Vector__XXX
 SG_ HFS_Unlock_Taster : 5|1@1+ (1,0) [0|1] "" Vector__XXX
 SG_ HFS_Lock_Taster : 6|1@1+ (1,0) [0|1] "" Vector__XXX
 SG_ HFS_Sperrklinke : 7|1@1+ (1,0) [0|1] "" Vector__XXX
 SG_ HFS_TAG_betaetigt : 8|1@1+ (1,0) [0|1] "" Vector__XXX
 SG_ HFS_TIG_betaetigt : 9|1@1+ (1,0) [0|1] "" Vector__XXX
 SG_ HFS_FH_S_HBFS_AutoHoch : 10|1@1+ (1,0) [0|1] "" Vector__XXX
 SG_ HFS_FH_S_HBFS_AutoTief : 11|1@1+ (1,0) [0|1] "" Vector__XXX
 SG_ HFS_FH_S_HBFS_ManHoch : 12|1@1+ (1,0) [0|1] "" Vector__XXX
 SG_ HFS_FH_S_HBFS_ManTief : 13|1@1+ (1,0) [0|1] "" Vector__XXX
 SG_ HFS_Tuer_Status : 14|2@1+ (1,0) [0|3] "" Vector__XXX
 SG_ HFS_SAD_Schalter : 16|4@1+ (1,0) [0|15] "" Vector__XXX
 SG_ HFS_FH_S_ManHoch : 20|1@1+ (1,0) [0|1] "" Vector__XXX
 SG_ HFS_FH_S_AutoHoch : 21|1@1+ (1,0) [0|1] "" Vector__XXX
 SG_ HFS_FH_S_ManTief : 22|1@1+ (1,0) [0|1] "" Vector__XXX
 SG_ HFS_FH_S_AutoTief : 23|1@1+ (1,0) [0|1] "" Vector__XXX
 SG_ HFS_FH_Oeffnung : 24|8@1+ (0.5,0) [0|100] "Unit_PerCent" Vector__XXX
 SG_ HFS_FH_Bew_hoch : 32|1@1+ (1,0) [0|1] "" Vector__XXX
 SG_ HFS_FH_Bew_tief : 33|1@1+ (1,0) [0|1] "" Vector__XXX
 SG_ HFS_FH_Fang : 34|1@1+ (1,0) [0|1] "" Vector__XXX
 SG_ HFS_FH_Block : 35|1@1+ (1,0) [0|1] "" Vector__XXX
 SG_ HFS_FH_Thermo : 36|1@1+ (1,0) [0|1] "" Vector__XXX
 SG_ HFS_UEKB_aktiviert : 37|1@1+ (1,0) [0|1] "" Vector__XXX
 SG_ HFS_Tueroeffnen_Warnung : 38|1@1+ (1,0) [0|1] "" Vector__XXX
 SG_ HFS_FH_normiert : 39|1@1+ (1,0) [0|1] "" Vector__XXX
 SG_ ASW_Warnung_aktiv_HFS : 40|1@1+ (1,0) [0|1] "" Vector__XXX
 SG_ HFS_Zuziehhilfe_aktiv : 41|1@1+ (1,0) [0|1] "" Vector__XXX
 SG_ HFS_Seitenrollo_hoch : 42|1@1+ (1,0) [0|1] ""  TME
 SG_ HFS_Seitenrollo_tief : 43|1@1+ (1,0) [0|1] ""  TME
 SG_ HFS_Status_KiSi : 44|1@1+ (1,0) [0|1] "" Vector__XXX
 SG_ SSR_HFS_Pos_Unten : 45|1@1+ (1,0) [0|1] "" Vector__XXX
 SG_ HFS_Oben_Block_erw : 46|1@1+ (1,0) [0|1] "" Vector__XXX
 SG_ HFS_Unten_Block_erw : 47|1@1+ (1,0) [0|1] "" Vector__XXX
 SG_ MTHFS_M_Taste : 48|1@1+ (1,0) [0|1] "" Vector__XXX
 SG_ MTHFS_Pos1 : 49|1@1+ (1,0) [0|1] "" Vector__XXX
 SG_ MTHFS_Pos2 : 50|1@1+ (1,0) [0|1] "" Vector__XXX
 SG_ MTHFS_Pos3 : 51|1@1+ (1,0) [0|1] "" Vector__XXX
 SG_ HFS_MRollo_Schalter : 52|3@1+ (1,0) [0|7] "" Vector__XXX
 SG_ HFS_Lock_Taster_inv : 55|1@1+ (1,0) [0|1] "" Vector__XXX
 SG_ HFS_Status_eTAG : 56|2@1+ (1,0) [0|3] "" Vector__XXX
 SG_ HFS_Tuer_Status_QBit : 58|1@1+ (1,0) [0|1] "" Vector__XXX
 SG_ HFS_TCR_Mode_aktiv : 59|1@1+ (1,0) [0|1] "" Vector__XXX

BO_ 975 TSG_HBFS_01: 8 Gateway
 SG_ HBFS_Tuer_geoeffnet : 0|1@1+ (1,0) [0|1] "" Vector__XXX
 SG_ HBFS_verriegelt : 1|1@1+ (1,0) [0|1] "" Vector__XXX
 SG_ HBFS_gesafet : 2|1@1+ (1,0) [0|1] "" Vector__XXX
 SG_ HBFS_Heckrollotaster_betaetigt : 3|1@1+ (1,0) [0|1] "" Vector__XXX
 SG_ HBFS_Tuerschloss_defekt : 4|1@1+ (1,0) [0|1] "" Vector__XXX
 SG_ HBFS_Unlock_Taster : 5|1@1+ (1,0) [0|1] "" Vector__XXX
 SG_ HBFS_Lock_Taster : 6|1@1+ (1,0) [0|1] "" Vector__XXX
 SG_ HBFS_Sperrklinke : 7|1@1+ (1,0) [0|1] "" Vector__XXX
 SG_ HBFS_TAG_betaetigt : 8|1@1+ (1,0) [0|1] "" Vector__XXX
 SG_ HBFS_TIG_betaetigt : 9|1@1+ (1,0) [0|1] "" Vector__XXX
 SG_ HBFS_FH_S_HFS_AutoHoch : 10|1@1+ (1,0) [0|1] "" Vector__XXX
 SG_ HBFS_FH_S_HFS_AutoTief : 11|1@1+ (1,0) [0|1] "" Vector__XXX
 SG_ HBFS_FH_S_HFS_ManHoch : 12|1@1+ (1,0) [0|1] "" Vector__XXX
 SG_ HBFS_FH_S_HFS_ManTief : 13|1@1+ (1,0) [0|1] "" Vector__XXX
 SG_ HBFS_Tuer_Status : 14|2@1+ (1,0) [0|3] "" Vector__XXX
 SG_ HBFS_SAD_Schalter : 16|4@1+ (1,0) [0|15] "" Vector__XXX
 SG_ HBFS_FH_S_ManHoch : 20|1@1+ (1,0) [0|1] "" Vector__XXX
 SG_ HBFS_FH_S_AutoHoch : 21|1@1+ (1,0) [0|1] "" Vector__XXX
 SG_ HBFS_FH_S_ManTief : 22|1@1+ (1,0) [0|1] "" Vector__XXX
 SG_ HBFS_FH_S_AutoTief : 23|1@1+ (1,0) [0|1] "" Vector__XXX
 SG_ HBFS_FH_Oeffnung : 24|8@1+ (0.5,0) [0|100] "Unit_PerCent" Vector__XXX
 SG_ HBFS_FH_Bew_hoch : 32|1@1+ (1,0) [0|1] "" Vector__XXX
 SG_ HBFS_FH_Bew_tief : 33|1@1+ (1,0) [0|1] "" Vector__XXX
 SG_ HBFS_FH_Fang : 34|1@1+ (1,0) [0|1] "" Vector__XXX
 SG_ HBFS_FH_Block : 35|1@1+ (1,0) [0|1] "" Vector__XXX
 SG_ HBFS_FH_Thermo : 36|1@1+ (1,0) [0|1] "" Vector__XXX
 SG_ HBFS_UEKB_aktiviert : 37|1@1+ (1,0) [0|1] "" Vector__XXX
 SG_ HBFS_Tueroeffnen_Warnung : 38|1@1+ (1,0) [0|1] "" Vector__XXX
 SG_ HBFS_FH_normiert : 39|1@1+ (1,0) [0|1] "" Vector__XXX
 SG_ ASW_Warnung_aktiv_HBFS : 40|1@1+ (1,0) [0|1] "" Vector__XXX
 SG_ HBFS_Zuziehhilfe_aktiv : 41|1@1+ (1,0) [0|1] "" Vector__XXX
 SG_ HBFS_Seitenrollo_hoch : 42|1@1+ (1,0) [0|1] ""  TME
 SG_ HBFS_Seitenrollo_tief : 43|1@1+ (1,0) [0|1] ""  TME
 SG_ HBFS_Status_KiSi : 44|1@1+ (1,0) [0|1] "" Vector__XXX
 SG_ SSR_HBFS_Pos_Unten : 45|1@1+ (1,0) [0|1] "" Vector__XXX
 SG_ HBFS_Oben_Block_erw : 46|1@1+ (1,0) [0|1] "" Vector__XXX
 SG_ HBFS_Unten_Block_erw : 47|1@1+ (1,0) [0|1] "" Vector__XXX
 SG_ MTHBFS_M_Taste : 48|1@1+ (1,0) [0|1] "" Vector__XXX
 SG_ MTHBFS_Pos1 : 49|1@1+ (1,0) [0|1] "" Vector__XXX
 SG_ MTHBFS_Pos2 : 50|1@1+ (1,0) [0|1] "" Vector__XXX
 SG_ MTHBFS_Pos3 : 51|1@1+ (1,0) [0|1] "" Vector__XXX
 SG_ HBFS_MRollo_Schalter : 52|3@1+ (1,0) [0|7] "" Vector__XXX
 SG_ HBFS_Lock_Taster_inv : 55|1@1+ (1,0) [0|1] "" Vector__XXX
 SG_ HBFS_Status_KiSi_inv : 56|1@1+ (1,0) [0|1] "" Vector__XXX
 SG_ HBFS_Status_eTAG : 57|2@1+ (1,0) [0|3] "" Vector__XXX
 SG_ HBFS_Tuer_Status_QBit : 59|1@1+ (1,0) [0|1] "" Vector__XXX
 SG_ HBFS_TIG_betaetigt_schliessen : 60|1@1+ (1,0) [0|1] "" Vector__XXX

BO_ 976 TSG_FT_01: 8 Gateway
 SG_ FT_Tuer_geoeffnet : 0|1@1+ (1,0) [0|1] ""  Ladegeraet_Konzern,TME
 SG_ FT_verriegelt : 1|1@1+ (1,0) [0|1] "" Vector__XXX
 SG_ FT_gesafet : 2|1@1+ (1,0) [0|1] "" Vector__XXX
 SG_ FT_Schluesselschalter_auf : 3|1@1+ (1,0) [0|1] ""  FCU_MLBevo_FCEV
 SG_ FT_Schluesselschalter_zu : 4|1@1+ (1,0) [0|1] ""  FCU_MLBevo_FCEV
 SG_ FT_Unlock_Taster : 5|1@1+ (1,0) [0|1] "" Vector__XXX
 SG_ FT_Lock_Taster : 6|1@1+ (1,0) [0|1] "" Vector__XXX
 SG_ FT_Sperrklinke : 7|1@1+ (1,0) [0|1] "" Vector__XXX
 SG_ FT_TAG_betaetigt : 8|1@1+ (1,0) [0|1] "" Vector__XXX
 SG_ FT_TIG_betaetigt : 9|1@1+ (1,0) [0|1] "" Vector__XXX
 SG_ FT_IRUE_Taste : 10|1@1+ (1,0) [0|1] "" Vector__XXX
 SG_ FT_HD_Taste : 11|1@1+ (1,0) [0|1] "" Vector__XXX
 SG_ FT_TD_Taste_Fehler : 12|1@1+ (1,0) [0|1] ""  Ladegeraet_Konzern
 SG_ FT_TD_Taste : 13|1@1+ (1,0) [0|1] ""  FCU_MLBevo_FCEV,Ladegeraet_Konzern
 SG_ SSR_Temp_Freigabe : 14|1@1+ (1,0) [0|1] "" Vector__XXX
 SG_ FT_Sp_Heizung_Anf : 15|1@1+ (100,0) [0|100] "Unit_PerCent" Vector__XXX
 SG_ FT_HD_Taste_2 : 16|1@1+ (1,0) [0|1] "" Vector__XXX
 SG_ FT_TSG_hinten_verbaut : 18|1@1+ (1,0) [0|1] "" Vector__XXX
 SG_ FT_Sp_Blk_def : 19|1@1+ (1,0) [0|1] "" Vector__XXX
 SG_ FT_FH_S_ManHoch : 20|1@1+ (1,0) [0|1] "" Vector__XXX
 SG_ FT_FH_S_AutoHoch : 21|1@1+ (1,0) [0|1] "" Vector__XXX
 SG_ FT_FH_S_ManTief : 22|1@1+ (1,0) [0|1] "" Vector__XXX
 SG_ FT_FH_S_AutoTief : 23|1@1+ (1,0) [0|1] "" Vector__XXX
 SG_ FT_FH_Oeffnung : 24|8@1+ (0.5,0) [0|100] "Unit_PerCent"  TME
 SG_ FT_FH_Bew_hoch : 32|1@1+ (1,0) [0|1] "" Vector__XXX
 SG_ FT_FH_Bew_tief : 33|1@1+ (1,0) [0|1] "" Vector__XXX
 SG_ FT_FH_Fang : 34|1@1+ (1,0) [0|1] "" Vector__XXX
 SG_ FT_FH_Block : 35|1@1+ (1,0) [0|1] "" Vector__XXX
 SG_ FT_FH_Thermo : 36|1@1+ (1,0) [0|1] "" Vector__XXX
 SG_ FT_UEKB_aktiviert : 37|1@1+ (1,0) [0|1] "" Vector__XXX
 SG_ ASW_HMI_defekt : 38|1@1+ (1,0) [0|1] "" Vector__XXX
 SG_ FT_FH_normiert : 39|1@1+ (1,0) [0|1] "" Vector__XXX
 SG_ FT_Schliesstaster : 40|1@1+ (1,0) [0|1] "" Vector__XXX
 SG_ FT_Zuziehhilfe_aktiv : 41|1@1+ (1,0) [0|1] "" Vector__XXX
 SG_ FT_SP_ausgerastet : 42|1@1+ (1,0) [0|1] "" Vector__XXX
 SG_ FT_SP_lr_aktiv : 43|1@1+ (1,0) [0|1] "" Vector__XXX
 SG_ FT_SP_ht_aktiv : 44|1@1+ (1,0) [0|1] "" Vector__XXX
 SG_ ASW_wakeup : 45|1@1+ (1,0) [0|1] "" Vector__XXX
 SG_ FT_Oben_Block_erw : 46|1@1+ (1,0) [0|1] "" Vector__XXX
 SG_ FT_Unten_Block_erw : 47|1@1+ (1,0) [0|1] "" Vector__XXX
 SG_ FT_Kisi_li_aktiv : 48|1@1+ (1,0) [0|1] "" Vector__XXX
 SG_ FT_Kisi_re_aktiv : 49|1@1+ (1,0) [0|1] "" Vector__XXX
 SG_ FT_Kisi_Taster_li : 50|1@1+ (1,0) [0|1] "" Vector__XXX
 SG_ FT_Kisi_Taster_re : 51|1@1+ (1,0) [0|1] "" Vector__XXX
 SG_ FT_BFS_Fond_Freigabe : 52|1@1+ (1,0) [0|1] "" Vector__XXX
 SG_ FT_Kisi_Fehler : 53|1@1+ (1,0) [0|1] "" Vector__XXX
 SG_ FT_Daemmglas : 54|1@1+ (1,0) [0|1] "" Vector__XXX
 SG_ FT_SP_Heizung_Status : 55|1@1+ (1,0) [0|1] "" Vector__XXX
 SG_ ASW_Warnung_aktiv_FS : 56|1@1+ (1,0) [0|1] "" Vector__XXX
 SG_ FT_FH_Pos_oben : 57|1@1+ (1,0) [0|1] "" Vector__XXX
 SG_ FT_Tuerschloss_defekt : 58|1@1+ (1,0) [0|1] "" Vector__XXX
 SG_ FT_SWA_Taster : 59|1@1+ (1,0) [0|1] "" Vector__XXX
 SG_ SWA_HMI_Diagnose : 60|2@1+ (1,0) [0|3] "" Vector__XXX
 SG_ FS_Status_eTAG : 62|2@1+ (1,0) [0|3] "" Vector__XXX

BO_ 64 Airbag_01: 8 Gateway
 SG_ Airbag_01_CRC : 0|8@1+ (1,0) [0|255] ""  AWC,BMC_MLBevo,BMS_NV,DCDC_800V_PAG,DCDC_HV,DCDC_HV_02,DCDC_IHEV,FCU_MLBevo_FCEV,Ladegeraet_2,Ladegeraet_Konzern,Sub_Gateway
 SG_ Airbag_01_BZ : 8|4@1+ (1,0) [0|15] ""  AWC,BMC_MLBevo,BMS_NV,DCDC_800V_PAG,DCDC_HV,DCDC_HV_02,DCDC_IHEV,FCU_MLBevo_FCEV,Ladegeraet_2,Ladegeraet_Konzern,Sub_Gateway
 SG_ AB_RGS_Anst : 12|4@1+ (1,0) [0|15] ""  FCU_MLBevo_FCEV,Sub_Gateway
 SG_ AB_Front_Crash : 16|1@1+ (1,0) [0|1] ""  FCU_MLBevo_FCEV,Sub_Gateway
 SG_ AB_Heck_Crash : 17|1@1+ (1,0) [0|1] ""  FCU_MLBevo_FCEV,Sub_Gateway
 SG_ AB_SF_Crash : 18|1@1+ (1,0) [0|1] ""  FCU_MLBevo_FCEV,Sub_Gateway
 SG_ AB_SB_Crash : 19|1@1+ (1,0) [0|1] ""  FCU_MLBevo_FCEV,Sub_Gateway
 SG_ AB_Rollover_Crash : 20|1@1+ (1,0) [0|1] ""  FCU_MLBevo_FCEV,Sub_Gateway
 SG_ AB_Crash_Int : 21|3@1+ (1,0) [0|7] ""  FCU_MLBevo_FCEV,Sub_Gateway,TME
 SG_ AB_Lampe : 24|1@1+ (1,0) [0|1] ""  FCU_MLBevo_FCEV,Sub_Gateway
 SG_ AB_Deaktiviert : 25|1@1+ (1,0) [0|1] ""  FCU_MLBevo_FCEV,Sub_Gateway
 SG_ AB_VB_deaktiviert : 26|1@1+ (1,0) [0|1] ""  FCU_MLBevo_FCEV,Sub_Gateway
 SG_ AB_Systemfehler : 27|1@1+ (1,0) [0|1] ""  FCU_MLBevo_FCEV,Sub_Gateway
 SG_ AB_Diagnose : 28|1@1+ (1,0) [0|1] ""  FCU_MLBevo_FCEV,Sub_Gateway
 SG_ AB_Stellgliedtest : 29|1@1+ (1,0) [0|1] ""  FCU_MLBevo_FCEV,Sub_Gateway,TME
 SG_ AB_Erh_Auf_VB : 30|2@1+ (1,0) [0|3] ""  FCU_MLBevo_FCEV,Sub_Gateway
 SG_ AB_Gurtwarn_VF : 32|1@1+ (1,0) [0|1] ""  FCU_MLBevo_FCEV,Sub_Gateway
 SG_ AB_Gurtwarn_VB : 33|1@1+ (1,0) [0|1] ""  FCU_MLBevo_FCEV,Sub_Gateway
 SG_ AB_Anzeige_Fussg : 34|2@1+ (1,0) [0|3] ""  FCU_MLBevo_FCEV,Sub_Gateway
 SG_ AB_Texte_AKS : 36|2@1+ (1,0) [0|3] ""  FCU_MLBevo_FCEV,Sub_Gateway
 SG_ AB_MKB_gueltig : 39|1@1+ (1,0) [0|1] ""  FCU_MLBevo_FCEV,Sub_Gateway
 SG_ AB_MKB_Anforderung : 40|1@1+ (1,0) [0|1] ""  FCU_MLBevo_FCEV,Sub_Gateway
 SG_ AB_Versorgungsspannung : 41|1@1+ (1,0) [0|1] ""  FCU_MLBevo_FCEV,Sub_Gateway
 SG_ AB_Deaktivierung_HV : 42|3@1+ (1,0) [0|7] ""  AWC,BMC_MLBevo,BMS_NV,DCDC_800V_PAG,DCDC_HV,DCDC_HV_02,DCDC_IHEV,FCU_MLBevo_FCEV,Ladegeraet_2,Ladegeraet_Konzern,Sub_Gateway,TME
 SG_ AB_EDR_Trigger : 45|2@1+ (1,0) [0|3] ""  FCU_MLBevo_FCEV,Sub_Gateway
 SG_ AB_Belegung_VF : 47|2@1+ (1,0) [0|3] ""  FCU_MLBevo_FCEV,Sub_Gateway
 SG_ SC_Masterzeit_Offset : 53|2@1+ (5.08,0) [0|15.24] "Unit_Secon"  FCU_MLBevo_FCEV,Sub_Gateway
 SG_ SC_LowSpeedCrashErkannt : 55|2@1+ (1,0) [0|3] ""  FCU_MLBevo_FCEV,Sub_Gateway
 SG_ SC_Masterzeit : 57|7@1+ (0.04,0) [0|5.04] "Unit_Secon"  FCU_MLBevo_FCEV,Sub_Gateway

BO_ 1312 Airbag_02: 8 Gateway
 SG_ CHECKSUM : 0|8@1+ (1,0) [0|255] ""  Vector__XXX
 SG_ COUNTER : 8|4@1+ (1,0) [0|15] ""  Vector__XXX
 SG_ LoGeWa_Event_Kombiwarnung : 12|4@1+ (1.0,0.0) [0.0|15] ""  ZR_High
 SG_ AB_Anforderung_eCall : 16|1@1+ (1.0,0.0) [0.0|1] ""  ZR_High
 SG_ AB_Anprall_Seite_Beifahrer : 17|1@1+ (1.0,0.0) [0.0|1] ""  Vector__XXX
 SG_ AB_Anprall_Rollover : 18|1@1+ (1.0,0.0) [0.0|1] ""  Vector__XXX
 SG_ AB_Anprall_FGS : 19|1@1+ (1.0,0.0) [0.0|1] ""  Vector__XXX
 SG_ AB_Anprall_Front_Beifahrer : 20|1@1+ (1.0,0.0) [0.0|1] ""  Vector__XXX
 SG_ AB_Anprall_Front_Fahrer : 21|1@1+ (1.0,0.0) [0.0|1] ""  Vector__XXX
 SG_ AB_Anprall_Heck_Beifahrer : 22|1@1+ (1.0,0.0) [0.0|1] ""  Vector__XXX
 SG_ AB_Anprall_Heck_Fahrer : 23|1@1+ (1.0,0.0) [0.0|1] ""  Vector__XXX
 SG_ AB_Wickelklappung_Reihe2_MI : 24|2@1+ (1.0,0.0) [0.0|3] ""  Vector__XXX
 SG_ AB_Belegung_VB : 26|2@1+ (1.0,0.0) [0.0|3] ""  BedienSG_hi,GurtMikrofon,ZR_High,ZR_LIMU,ZR_MIB_TOP_ab_Gen3
 SG_ AB_Abschaltanf_SIH_BF : 28|1@1+ (1.0,0.0) [0.0|1] ""  ZR_High
 SG_ AB_Anprall_Seite_Fahrer : 29|1@1+ (1.0,0.0) [0.0|1] ""  Vector__XXX
 SG_ SC_PAO_Schriftzug_Anf : 30|2@1+ (1.0,0.0) [0.0|3] ""  ZR_High
 SG_ SC_PAO_ON_Anf : 32|2@1+ (1.0,0.0) [0.0|3] ""  ZR_High
 SG_ SC_PAO_OFF_Anf : 34|2@1+ (1.0,0.0) [0.0|3] ""  ZR_High
 SG_ AB_Crashschwere : 36|3@1+ (1.0,0.0) [0.0|7] ""  Vector__XXX
 SG_ AB_Anforderung_USM : 39|1@1+ (1.0,0.0) [0.0|1] ""  ZR_Standard
 SG_ AB_Gurtschloss_FA : 40|2@1+ (1.0,0.0) [0.0|3] ""  BedienSG_hi,GurtMikrofon,ZR_High
 SG_ AB_Gurtschloss_BF : 42|2@1+ (1.0,0.0) [0.0|3] ""  BedienSG_hi,GurtMikrofon,ZR_High,ZR_LIMU,ZR_MIB_TOP_ab_Gen3
 SG_ AB_Gurtschloss_Reihe2_FA : 44|2@1+ (1.0,0.0) [0.0|3] ""  BedienSG_hi,ZR_High,ZR_LIMU,ZR_MIB_TOP_ab_Gen3
 SG_ AB_Gurtschloss_Reihe2_MI : 46|2@1+ (1.0,0.0) [0.0|3] ""  BedienSG_hi,ZR_High,ZR_LIMU,ZR_MIB_TOP_ab_Gen3
 SG_ AB_Gurtschloss_Reihe2_BF : 48|2@1+ (1.0,0.0) [0.0|3] ""  BedienSG_hi,ZR_High,ZR_LIMU,ZR_MIB_TOP_ab_Gen3
 SG_ AB_Gurtschloss_Reihe3_FA : 50|2@1+ (1.0,0.0) [0.0|3] ""  BedienSG_hi,ZR_High
 SG_ AB_Gurtschloss_Reihe3_MI : 52|2@1+ (1.0,0.0) [0.0|3] ""  BedienSG_hi,ZR_High
 SG_ AB_Gurtschloss_Reihe3_BF : 54|2@1+ (1.0,0.0) [0.0|3] ""  BedienSG_hi,ZR_High
 SG_ AB_Sitzpos_Sens_FA : 56|2@1+ (1.0,0.0) [0.0|3] ""  ZR_High
 SG_ AB_Sitzpos_Sens_BF : 58|2@1+ (1.0,0.0) [0.0|3] ""  ZR_High
 SG_ AB_Wickelklappung_Reihe2_BF : 60|2@1+ (1.0,0.0) [0.0|3] ""  ZR_High
 SG_ AB_Wickelklappung_Reihe2_FA : 62|2@1+ (1.0,0.0) [0.0|3] ""  ZR_High

BO_ 1601 Motor_Code_01: 8 Motor_Diesel_MQB
 SG_ Motor_Code_01_CRC : 0|8@1+ (1,0) [0|255] "" Gateway_MQB
 SG_ Motor_Code_01_BZ : 8|4@1+ (1,0) [0|15] "" Gateway_MQB
 SG_ MO_Faktor_Momente_02 : 12|2@1+ (1,0) [0|3] "" Gateway_MQB,Getriebe_DQ_Hybrid_MQB,Getriebe_DQ_MQB
 SG_ MO_Hybridfahrzeug : 14|2@1+ (1,0) [0|3] "" Gateway_MQB
 SG_ MO_Code : 16|8@1+ (1,0) [0|255] "" Gateway_MQB,SAK_MQB
 SG_ MO_Getriebe_Code : 24|6@1+ (1,0) [0|63] "" Gateway_MQB
 SG_ MO_StartStopp_Codiert : 30|1@1+ (1,0) [0|1] "" Gateway_MQB
 SG_ MO_Anzahl_Zyl : 32|4@1+ (1,0) [0|15] "" Gateway_MQB
 SG_ MO_Kraftstoffart : 36|4@1+ (1,0) [0|15] "" Gateway_MQB,Getriebe_DQ_Hybrid_MQB,Getriebe_DQ_MQB
 SG_ MO_Hubraum : 40|7@1+ (0.1,0) [0|12.7] "Unit_Liter" Gateway_MQB
 SG_ MO_Ansaugsystem : 47|1@1+ (1,0) [0|1] "" Gateway_MQB
 SG_ MO_Leistung : 48|9@1+ (1,0) [0|511] "Unit_KiloWatt" Gateway_MQB
 SG_ MO_Abgastyp_EOBD : 57|1@1+ (1,0) [0|1] "" BMS_MQB,Gateway_MQB,LEH_MQB
 SG_ MO_Abgastyp_OBD : 58|1@1+ (1,0) [0|1] "" BMS_MQB,Gateway_MQB,LEH_MQB
 SG_ MO_DPF_verbaut : 59|1@1+ (1,0) [0|1] "" Gateway_MQB
 SG_ TSK_Codierung : 60|3@1+ (1,0) [0|7] "" Gateway_MQB,Getriebe_DQ_Hybrid_MQB,Getriebe_DQ_MQB
 SG_ MO_Einspritzart : 63|1@1+ (1,0) [0|1] "" Gateway_MQB

BO_ 1603 Einheiten_01: 8 Gateway
 SG_ KBI_Einheit_Datum : 0|2@1+ (1,0) [0|3] "" Vector__XXX
 SG_ KBI_Einheit_Druck : 2|2@1+ (1,0) [0|3] "" Vector__XXX
 SG_ KBI_Einheit_Streckenanz : 4|1@1+ (1,0) [0|1] ""  Ladegeraet_Konzern
 SG_ KBI_MFA_v_Einheit_02 : 5|1@1+ (1,0) [0|1] "" Vector__XXX
 SG_ KBI_Einheit_Temp : 6|1@1+ (1,0) [0|1] ""  TME
 SG_ KBI_Einheit_Uhrzeit : 7|1@1+ (1,0) [0|1] ""  Ladegeraet_Konzern
 SG_ KBI_Einheit_Verbrauch : 8|2@1+ (1,0) [0|3] "" Vector__XXX
 SG_ KBI_Einheit_Volumen : 10|2@1+ (1,0) [0|3] "" Vector__XXX
 SG_ KBI_Einheit_Verbrauch_elektr : 12|3@1+ (1,0) [0|7] "" Vector__XXX
 SG_ KBI_Einheit_Sprache : 16|8@1+ (1,0) [0|255] "" Vector__XXX
 SG_ KBI_Einheit_Verbrauch_Gas : 24|4@1+ (1,0) [0|15] "" Vector__XXX
 SG_ KBI_Einheit_Masse : 28|2@1+ (1,0) [0|3] "" Vector__XXX

BO_ 1629 ESP_20: 8 Gateway
 SG_ ESP_20_CRC : 0|8@1+ (1,0) [0|255] "" Vector__XXX
 SG_ ESP_20_BZ : 8|4@1+ (1,0) [0|15] "" Vector__XXX
 SG_ BR_Systemart : 12|2@1+ (1,0) [0|3] "" Vector__XXX
 SG_ ESP_SpannungsAnf_02 : 14|2@1+ (1,0) [0|3] "" Vector__XXX
 SG_ ESP_Zaehnezahl : 16|8@1+ (1,0) [0|255] "" Vector__XXX
 SG_ ESP_Charisma_FahrPr : 24|4@1+ (1,0) [0|15] "" Vector__XXX
 SG_ ESP_Charisma_Status : 28|2@1+ (1,0) [0|3] "" Vector__XXX
 SG_ ESP_Wiederstart_Anz_01 : 30|1@1+ (1,0) [0|1] "" Vector__XXX
 SG_ ESP_Wiederstart_Anz_02 : 31|1@1+ (1,0) [0|1] "" Vector__XXX
 SG_ ESP_Wiederstart_Anz_03 : 32|1@1+ (1,0) [0|1] "" Vector__XXX
 SG_ ESP_Wiederstart_Anz_04 : 33|1@1+ (1,0) [0|1] "" Vector__XXX
 SG_ ESP_Stoppverbot_Anz_01 : 34|1@1+ (1,0) [0|1] "" Vector__XXX
 SG_ ESP_Stoppverbot_Anz_02 : 35|1@1+ (1,0) [0|1] "" Vector__XXX
 SG_ ESP_Stoppverbot_Anz_03 : 36|1@1+ (1,0) [0|1] "" Vector__XXX
 SG_ ESP_Stoppverbot_Anz_04 : 37|1@1+ (1,0) [0|1] "" Vector__XXX
 SG_ ESP_Stoppverbot_Anz_05 : 38|1@1+ (1,0) [0|1] "" Vector__XXX
 SG_ ESP_Stoppverbot_Anz_06 : 39|1@1+ (1,0) [0|1] "" Vector__XXX
 SG_ ESP_Stoppverbot_Anz_07 : 40|1@1+ (1,0) [0|1] "" Vector__XXX
 SG_ ESP_Stoppverbot_Anz_Std : 41|1@1+ (1,0) [0|1] "" Vector__XXX
 SG_ ESP_Dachrelingsensor : 42|2@1+ (1,0) [0|3] "" Vector__XXX
 SG_ ESP_Stoppverbot_Anz_08 : 44|1@1+ (1,0) [0|1] "" Vector__XXX
 SG_ HDC_Charisma_FahrPr : 45|4@1+ (1,0) [0|15] "" Vector__XXX
 SG_ HDC_Charisma_Status : 49|2@1+ (1,0) [0|3] "" Vector__XXX
 SG_ BR_QBit_Reifenumfang : 51|1@1+ (1,0) [0|1] ""  AWC
 SG_ BR_Reifenumfang : 52|12@1+ (1,0) [0|4095] "Unit_MilliMeter"  AWC

BO_ 1413 Systeminfo_01: 8 Gateway_MQB
 SG_ SI_Sammel_SG_Fehler : 0|6@1+ (1,0) [0|60] "" Vector__XXX
 SG_ SI_Rollenmode : 6|2@1+ (1,0) [0|3] "" Vector__XXX
 SG_ SI_QRS_Mode : 8|1@1+ (1,0) [0|1] "" Motor_Diesel_MQB,Motor_Hybrid_MQB,Motor_Otto_MQB
 SG_ SI_T_Mode : 9|1@1+ (1,0) [0|1] "" Vector__XXX
 SG_ SI_NWDF : 10|1@1+ (1,0) [0|1] "" SAK_MQB
 SG_ SI_NWDF_gueltig : 11|1@1+ (1,0) [0|1] "" SAK_MQB
 SG_ SI_Sammelfehler : 12|1@1+ (1,0) [0|1] "" Vector__XXX
 SG_ GW_KD_Fehler : 13|1@1+ (1,0) [0|1] "" Vector__XXX
 SG_ SI_BUS_01 : 16|1@1+ (1,0) [0|1] "" Vector__XXX
 SG_ SI_BUS_02 : 17|1@1+ (1,0) [0|1] "" Vector__XXX
 SG_ SI_BUS_03 : 18|1@1+ (1,0) [0|1] "" Vector__XXX
 SG_ SI_BUS_04 : 19|1@1+ (1,0) [0|1] "" Vector__XXX
 SG_ SI_BUS_05 : 20|1@1+ (1,0) [0|1] "" Vector__XXX
 SG_ SI_BUS_06 : 21|1@1+ (1,0) [0|1] "" Vector__XXX
 SG_ SI_BUS_07 : 22|1@1+ (1,0) [0|1] "" Vector__XXX
 SG_ SI_BUS_08 : 23|1@1+ (1,0) [0|1] "" Vector__XXX
 SG_ SI_BUS_09 : 24|1@1+ (1,0) [0|1] "" Vector__XXX
 SG_ SI_BUS_10 : 25|1@1+ (1,0) [0|1] "" Vector__XXX
 SG_ SI_BUS_11 : 26|1@1+ (1,0) [0|1] "" Vector__XXX
 SG_ SI_BUS_12 : 27|1@1+ (1,0) [0|1] "" Vector__XXX
 SG_ SI_BUS_13 : 28|1@1+ (1,0) [0|1] "" Vector__XXX
 SG_ SI_BUS_14 : 29|1@1+ (1,0) [0|1] "" Vector__XXX
 SG_ SI_BUS_15 : 30|1@1+ (1,0) [0|1] "" Vector__XXX

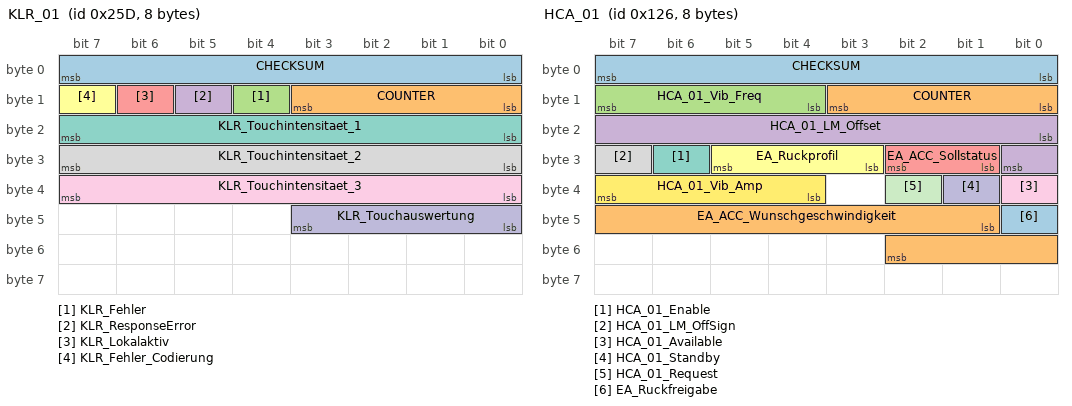
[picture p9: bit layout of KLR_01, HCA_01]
BO_ 605 KLR_01: 8 Gateway
 SG_ CHECKSUM : 0|8@1+ (1,0) [0|255] ""  Vector__XXX
 SG_ COUNTER : 8|4@1+ (1,0) [0|15] ""  Vector__XXX
 SG_ KLR_Fehler : 12|1@1+ (1.0,0.0) [0.0|1] ""  Vector__XXX
 SG_ KLR_ResponseError : 13|1@1+ (1.0,0.0) [0.0|1] ""  Vector__XXX
 SG_ KLR_Lokalaktiv : 14|1@1+ (1.0,0.0) [0.0|1] ""  Vector__XXX
 SG_ KLR_Fehler_Codierung : 15|1@1+ (1.0,0.0) [0.0|1] ""  Vector__XXX
 SG_ KLR_Touchintensitaet_1 : 16|8@1+ (1,0) [0|250] "Unit_None"  Vector__XXX
 SG_ KLR_Touchintensitaet_2 : 24|8@1+ (1,0) [0|250] "Unit_None"  Vector__XXX
 SG_ KLR_Touchintensitaet_3 : 32|8@1+ (1,0) [0|250] "Unit_None"  Vector__XXX
 SG_ KLR_Touchauswertung : 40|4@1+ (1.0,0.0) [0.0|15] ""  ZR_High

BO_ 294 HCA_01: 8 Frontsensorik
 SG_ CHECKSUM : 0|8@1+ (1,0) [0|255] "" Vector__XXX
 SG_ COUNTER : 8|4@1+ (1,0) [0|15] "" Vector__XXX
 SG_ HCA_01_Vib_Freq : 12|4@1+ (1,15) [15|30] "Unit_Hertz" Vector__XXX
 SG_ HCA_01_LM_Offset : 16|9@1+ (1,0) [0|511] "Unit_centiNewtoMeter" Vector__XXX
 SG_ EA_ACC_Sollstatus : 25|2@1+ (1,0) [0|3] ""  Frontradar
 SG_ EA_Ruckprofil : 27|3@1+ (1,0) [0|7] "" Vector__XXX
 SG_ HCA_01_Enable : 30|1@1+ (1,0) [0|1] "" Vector__XXX
 SG_ HCA_01_LM_OffSign : 31|1@1+ (1,0) [0|1] "" Vector__XXX
 SG_ HCA_01_Available : 32|1@1+ (1,0) [0|1] "" Vector__XXX
 SG_ HCA_01_Standby : 33|1@1+ (1,0) [0|1] "" Vector__XXX
 SG_ HCA_01_Request : 34|1@1+ (1,0) [0|1] "" Vector__XXX
 SG_ HCA_01_Vib_Amp : 36|4@1+ (0.2,0) [0|3] "Unit_NewtoMeter" Vector__XXX
 SG_ EA_Ruckfreigabe : 40|1@1+ (1,0) [0|1] "" Vector__XXX
 SG_ EA_ACC_Wunschgeschwindigkeit : 41|10@1+ (0.32,0) [0|327.04] "Unit_KiloMeterPerHour"  Frontradar

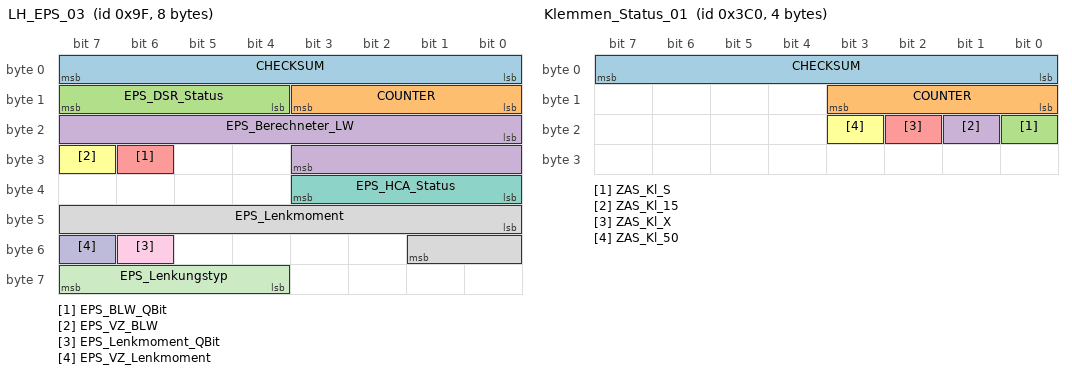
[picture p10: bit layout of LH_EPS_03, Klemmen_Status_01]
BO_ 159 LH_EPS_03: 8 XXX
 SG_ CHECKSUM : 0|8@1+ (1,0) [0|255] ""  XXX
 SG_ COUNTER : 8|4@1+ (1,0) [0|15] ""  XXX
 SG_ EPS_DSR_Status : 12|4@1+ (1,0) [0|15] ""  XXX
 SG_ EPS_Berechneter_LW : 16|12@1+ (0.15,0) [0|613.95] "Unit_DegreOfArc"  XXX
 SG_ EPS_BLW_QBit : 30|1@1+ (1,0) [0|1] ""  XXX
 SG_ EPS_VZ_BLW : 31|1@1+ (1,0) [0|1] ""  XXX
 SG_ EPS_HCA_Status : 32|4@1+ (1,0) [0|15] ""  XXX
 SG_ EPS_Lenkmoment : 40|10@1+ (1,0) [0|8] "Unit_centiNewtoMeter"  XXX
 SG_ EPS_Lenkmoment_QBit : 54|1@1+ (1,0) [0|1] ""  XXX
 SG_ EPS_VZ_Lenkmoment : 55|1@1+ (1,0) [0|1] ""  XXX
 SG_ EPS_Lenkungstyp : 60|4@1+ (1,0) [0|15] ""  XXX

BO_ 919 LDW_02: 8 XXX
 SG_ LDW_Gong : 12|2@1+ (1,0) [0|3] ""  XXX
 SG_ LDW_SW_Warnung_links : 14|1@1+ (1,0) [0|1] ""  XXX
 SG_ LDW_SW_Warnung_rechts : 15|1@1+ (1,0) [0|1] ""  XXX
 SG_ LDW_Texte : 16|4@1+ (1,0) [0|15] ""  XXX
 SG_ LDW_Seite_DLCTLC : 20|1@1+ (1,0) [0|1] ""  XXX
 SG_ LDW_Lernmodus : 21|3@1+ (1,0) [0|7] ""  XXX
 SG_ LDW_Anlaufsp_VLR : 24|4@1+ (1,0) [0|15] ""  XXX
 SG_ LDW_Vib_Amp_VLR : 28|4@1+ (1,0) [0|15] ""  XXX
 SG_ LDW_Anlaufzeit_VLR : 32|4@1+ (1,0) [0|15] ""  XXX
 SG_ LDW_Lernmodus_rechts : 36|2@1+ (1,0) [0|3] ""  XXX
 SG_ LDW_Lernmodus_links : 38|2@1+ (1,0) [0|3] ""  XXX
 SG_ LDW_DLC : 40|8@1+ (0.01,-1.25) [-1.25|1.25] "Unit_Meter"  XXX
 SG_ LDW_TLC : 48|5@1+ (0.1,0) [0|3] "Unit_Secon"  XXX
 SG_ LDW_Warnung_links : 56|1@1+ (1,0) [0|1] ""  XXX
 SG_ LDW_Warnung_rechts : 57|1@1+ (1,0) [0|1] ""  XXX
 SG_ LDW_Codierinfo_fuer_VLR : 58|2@1+ (1,0) [0|3] ""  XXX
 SG_ LDW_Frontscheibenheizung_aktiv : 60|1@1+ (1,0) [0|1] ""  XXX
 SG_ LDW_Status_LED_gelb : 61|1@1+ (1,0) [0|1] ""  XXX
 SG_ LDW_Status_LED_gruen : 62|1@1+ (1,0) [0|1] ""  XXX
 SG_ LDW_KD_Fehler : 63|1@1+ (1,0) [0|1] ""  XXX

BO_ 960 Klemmen_Status_01: 4 Gateway_MQB
 SG_ CHECKSUM : 0|8@1+ (1,0) [0|255] "" Airbag_MQB,BMS_MQB,Motor_Diesel_MQB,Motor_Hybrid_MQB,Motor_Otto_MQB
 SG_ COUNTER : 8|4@1+ (1,0) [0|15] "" Airbag_MQB,BMS_MQB,Motor_Diesel_MQB,Motor_Hybrid_MQB,Motor_Otto_MQB
 SG_ ZAS_Kl_S : 16|1@1+ (1,0) [0|1] "" Vector__XXX
 SG_ ZAS_Kl_15 : 17|1@1+ (1,0) [0|1] "" Airbag_MQB,BMS_MQB,Motor_Diesel_MQB,Motor_Hybrid_MQB,Motor_Otto_MQB
 SG_ ZAS_Kl_X : 18|1@1+ (1,0) [0|1] "" Vector__XXX
 SG_ ZAS_Kl_50 : 19|1@1+ (1,0) [0|1] "" Vector__XXX

BO_ 1175 Parkhilfe_01: 8 Gateway
 SG_ PH_Visualisierung : 0|3@1+ (1,0) [0|7] ""  AWC
 SG_ PDC_Tonausgabe_Front : 4|4@1+ (1,0) [0|15] "" Vector__XXX
 SG_ PDC_Tonausgabe_Heck : 8|4@1+ (1,0) [0|15] "" Vector__XXX
 SG_ PH_nachtr_Stopp_Anf : 12|1@1+ (1,0) [0|1] "" Vector__XXX
 SG_ PH_Abschaltursache : 13|3@1+ (1,0) [0|7] ""  AWC
 SG_ PH_Opt_Anzeige_V_ein : 16|1@1+ (1,0) [0|1] "" Vector__XXX
 SG_ PH_Opt_Anzeige_H_ein : 17|1@1+ (1,0) [0|1] "" Vector__XXX
 SG_ PH_Opt_Anz_V_Hindernis : 18|1@1+ (1,0) [0|1] "" Vector__XXX
 SG_ PH_Opt_Anz_H_Hindernis : 19|1@1+ (1,0) [0|1] "" Vector__XXX
 SG_ PH_Tongeber_V_aktiv : 20|1@1+ (1,0) [0|1] "" Vector__XXX
 SG_ PH_Tongeber_H_aktiv : 21|1@1+ (1,0) [0|1] "" Vector__XXX
 SG_ PH_Tongeber_mute : 22|1@1+ (1,0) [0|1] "" Vector__XXX
 SG_ PH_Anf_Audioabsenkung : 23|1@1+ (1,0) [0|1] "" Vector__XXX
 SG_ PH_Tongeber_H_verfuegbar : 24|1@1+ (1,0) [0|1] "" Vector__XXX
 SG_ PLA_Anf_Aufschaltung_RVC : 25|1@1+ (1,0) [0|1] "" Vector__XXX
 SG_ PH_Taster : 28|2@1+ (1,0) [0|3] "" Vector__XXX
 SG_ PH_Anf_Verdeck : 30|2@1+ (1,0) [0|3] "" Vector__XXX
 SG_ PH_Frequenz_hinten : 32|4@1+ (1,0) [0|15] "" Vector__XXX
 SG_ PH_Lautstaerke_hinten : 36|4@1+ (1,0) [0|15] "" Vector__XXX
 SG_ PH_Frequenz_vorn : 40|4@1+ (1,0) [0|15] "" Vector__XXX
 SG_ PH_Lautstaerke_vorn : 44|4@1+ (1,0) [0|15] "" Vector__XXX
 SG_ PH_StartStopp_Info : 49|2@1+ (1,0) [0|3] "" Vector__XXX
 SG_ PH_Stoermeldung : 52|4@1+ (1,0) [0|15] "" Vector__XXX
 SG_ PH_defekt : 56|1@1+ (1,0) [0|1] "" Vector__XXX
 SG_ PH_gestoert : 57|1@1+ (1,0) [0|1] "" Vector__XXX
 SG_ PH_Systemzustand : 58|3@1+ (1,0) [0|7] ""  AWC
 SG_ PH_Display_Kundenwunsch : 61|2@1+ (1,0) [0|3] "" Vector__XXX

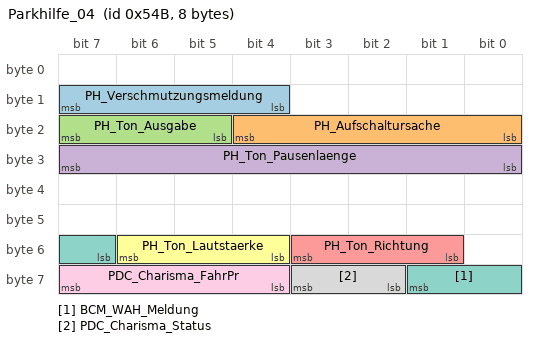
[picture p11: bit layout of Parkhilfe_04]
BO_ 1355 Parkhilfe_04: 8 Gateway
 SG_ PH_Verschmutzungsmeldung : 12|4@1+ (1,0) [0|15] "" Vector__XXX
 SG_ PH_Aufschaltursache : 16|5@1+ (1,0) [0|31] ""  AWC
 SG_ PH_Ton_Ausgabe : 21|3@1+ (1,0) [0|7] "" Vector__XXX
 SG_ PH_Ton_Pausenlaenge : 24|8@1+ (1,0) [0|255] "" Vector__XXX
 SG_ PH_Ton_Richtung : 49|3@1+ (1,0) [0|7] "" Vector__XXX
 SG_ PH_Ton_Lautstaerke : 52|3@1+ (1,0) [0|7] "" Vector__XXX
 SG_ BCM_WAH_Meldung : 55|3@1+ (1,0) [0|7] "" Vector__XXX
 SG_ PDC_Charisma_Status : 58|2@1+ (1,0) [0|3] "" Vector__XXX
 SG_ PDC_Charisma_FahrPr : 60|4@1+ (1,0) [0|15] "" Vector__XXX

BO_ 252 MEB_ESP_01: 48 XXX
 SG_ CHECKSUM : 0|8@1+ (1,0) [0|255] "" Vector__XXX
 SG_ COUNTER : 8|4@1+ (1,0) [0|15] "" Vector__XXX
 SG_ Accelerator_Higher_Speed : 40|1@0+ (1,0) [0|1] "" XXX
 SG_ NEW_SIGNAL_1 : 59|4@0+ (1,0) [0|15] "" XXX
 SG_ VL_Radgeschw : 72|8@1+ (0.53,0) [0|127] "Unit_MeterPerSecond" XXX
 SG_ VR_Radgeschw : 88|8@1+ (0.53,0) [0|127] "Unit_MeterPerSecond" XXX
 SG_ HL_Radgeschw : 104|8@1+ (0.53,0) [0|127] "Unit_MeterPerSecond" XXX
 SG_ HR_Radgeschw : 120|8@1+ (0.53,0) [0|127] "Unit_MeterPerSecond" XXX
 SG_ VL_Brake_Pressure : 156|5@0+ (1,0) [0|15] "" XXX
 SG_ VR_Brake_Pressure : 164|5@0+ (1,0) [0|15] "" XXX
 SG_ HL_Brake_Pressure : 172|5@0+ (1,0) [0|15] "" XXX
 SG_ HR_Brake_Pressure : 180|5@0+ (1,0) [0|15] "" XXX

BO_ 771 MEB_Lane_Assist_01: 24 XXX
 SG_ Inactive : 13|1@0+ (1,0) [0|1] "" XXX
 SG_ Active : 14|1@0+ (1,0) [0|3] "" XXX
 SG_ Data_01 : 16|7@1+ (1,0) [0|127] "" XXX
 SG_ Data_02 : 24|8@1+ (1,0) [0|255] "" XXX
 SG_ Contact : 34|3@0+ (1,0) [0|7] "" XXX
 SG_ VZ : 39|1@0+ (1,0) [0|1] "" XXX
 SG_ Active_02 : 66|1@0+ (1,0) [0|1] "" XXX

BO_ 588 MEB_Drive_State_01: 16 XXX
 SG_ Lower_Speed_01 : 32|1@0+ (1,0) [0|1] "" XXX
 SG_ Higher_Speed_01 : 33|1@0+ (1,0) [0|1] "" XXX
 SG_ Higher_Speed_02 : 83|1@0+ (1,0) [0|1] "" XXX
 SG_ Lower_Speed_02 : 84|1@0+ (1,0) [0|1] "" XXX
 SG_ Standstill : 86|1@0+ (1,0) [0|1] "" XXX
 SG_ NEW_SIGNAL_1 : 98|1@0+ (1,0) [0|1] "" XXX
 SG_ NEW_SIGNAL_6 : 119|1@0+ (1,0) [0|1] "" XXX

BO_ 589 MEB_Side_Assist_01: 64 XXX
 SG_ NEW_SIGNAL_1 : 15|4@0+ (1,0) [0|15] "" XXX
 SG_ NEW_SIGNAL_2 : 21|13@0+ (1,0) [0|8191] "" XXX
 SG_ NEW_SIGNAL_3 : 34|3@0+ (1,0) [0|7] "" XXX
 SG_ NEW_SIGNAL_4 : 55|1@0+ (1,0) [0|1] "" XXX
 SG_ NEW_SIGNAL_5 : 56|1@0+ (1,0) [0|1] "" XXX
 SG_ NEW_SIGNAL_9 : 60|1@0+ (1,0) [0|1] "" XXX
 SG_ NEW_SIGNAL_7 : 87|8@0+ (1,0) [0|255] "" XXX
 SG_ NEW_SIGNAL_10 : 89|2@0+ (1,0) [0|3] "" XXX
 SG_ NEW_SIGNAL_8 : 95|4@0+ (1,0) [0|3] "" XXX
 SG_ NEW_SIGNAL_11 : 97|2@0+ (1,0) [0|3] "" XXX
 SG_ NEW_SIGNAL_41 : 105|2@0+ (1,0) [0|3] "" XXX
 SG_ NEW_SIGNAL_13 : 116|1@0+ (1,0) [0|1] "" XXX
 SG_ NEW_SIGNAL_12 : 119|2@0+ (1,0) [0|3] "" XXX
 SG_ NEW_SIGNAL_14 : 121|2@0+ (1,0) [0|3] "" XXX
 SG_ NEW_SIGNAL_15 : 135|8@0+ (1,0) [0|65535] "" XXX
 SG_ NEW_SIGNAL_6 : 143|8@0+ (1,0) [0|255] "" XXX
 SG_ NEW_SIGNAL_16 : 151|8@0+ (1,0) [0|255] "" XXX
 SG_ NEW_SIGNAL_17 : 159|8@0+ (1,0) [0|255] "" XXX
 SG_ NEW_SIGNAL_18 : 167|8@0+ (1,0) [0|255] "" XXX
 SG_ NEW_SIGNAL_19 : 175|16@0+ (1,0) [0|65535] "" XXX
 SG_ NEW_SIGNAL_20 : 191|8@0+ (1,0) [0|255] "" XXX
 SG_ NEW_SIGNAL_21 : 262|7@0+ (1,0) [0|127] "" XXX
 SG_ NEW_SIGNAL_22 : 270|7@0+ (1,0) [0|127] "" XXX
 SG_ NEW_SIGNAL_23 : 279|8@0+ (1,0) [0|255] "" XXX
 SG_ NEW_SIGNAL_24 : 286|9@0+ (1,0) [0|511] "" XXX
 SG_ NEW_SIGNAL_25 : 292|2@0+ (1,0) [0|3] "" XXX
 SG_ NEW_SIGNAL_26 : 303|10@0+ (1,0) [0|1023] "" XXX
 SG_ NEW_SIGNAL_27 : 308|4@0+ (1,0) [0|15] "" XXX
 SG_ NEW_SIGNAL_28 : 318|7@0+ (1,0) [0|127] "" XXX
 SG_ NEW_SIGNAL_30 : 391|8@0+ (1,0) [0|3] "" XXX
 SG_ NEW_SIGNAL_32 : 399|8@0+ (1,0) [0|255] "" XXX
 SG_ NEW_SIGNAL_33 : 400|1@0+ (1,0) [0|1] "" XXX
 SG_ NEW_SIGNAL_35 : 410|3@0+ (1,0) [0|7] "" XXX
 SG_ NEW_SIGNAL_34 : 413|2@0+ (1,0) [0|3] "" XXX
 SG_ NEW_SIGNAL_37 : 428|4@0+ (1,0) [0|15] "" XXX
 SG_ NEW_SIGNAL_36 : 430|1@0+ (1,0) [0|1] "" XXX
 SG_ NEW_SIGNAL_38 : 439|7@0+ (1,0) [0|127] "" XXX
 SG_ NEW_SIGNAL_40 : 447|8@0+ (1,0) [0|63] "" XXX

BO_ 591 MEB_Distance_01: 64 XXX
 SG_ NEW_SIGNAL_23 : 16|1@0+ (1,0) [0|1] "" XXX
 SG_ NEW_SIGNAL_10 : 21|1@0+ (1,0) [0|1] "" XXX
 SG_ NEW_SIGNAL_9 : 22|1@0+ (1,0) [0|1] "" XXX
 SG_ NEW_SIGNAL_7 : 23|1@1+ (1,0) [0|3] "" XXX
 SG_ NEW_SIGNAL_13 : 24|1@0+ (1,0) [0|1] "" XXX
 SG_ NEW_SIGNAL_8 : 25|1@0+ (1,0) [0|3] "" XXX
 SG_ NEW_SIGNAL_27 : 26|1@0+ (1,0) [0|1] "" XXX
 SG_ NEW_SIGNAL_22 : 27|1@0+ (1,0) [0|1] "" XXX
 SG_ NEW_SIGNAL_11 : 28|1@0+ (1,0) [0|1] "" XXX
 SG_ NEW_SIGNAL_17 : 29|1@0+ (1,0) [0|1] "" XXX
 SG_ ACC_Ready : 30|1@0+ (1,0) [0|1] "" XXX
 SG_ NEW_SIGNAL_19 : 31|1@0+ (1,0) [0|1] "" XXX
 SG_ NEW_SIGNAL_15 : 32|1@0+ (1,0) [0|1] "" XXX
 SG_ NEW_SIGNAL_12 : 33|1@0+ (1,0) [0|1] "" XXX
 SG_ NEW_SIGNAL_14 : 43|1@0+ (1,0) [0|1] "" XXX
 SG_ NEW_SIGNAL_20 : 47|1@0+ (1,0) [0|1] "" XXX
 SG_ NEW_SIGNAL_21 : 49|1@0+ (1,0) [0|1] "" XXX
 SG_ NEW_SIGNAL_16 : 50|1@0+ (1,0) [0|1] "" XXX
 SG_ NEW_SIGNAL_5 : 53|1@0+ (1,0) [0|1] "" XXX
 SG_ NEW_SIGNAL_4 : 55|2@0+ (1,0) [0|3] "" XXX
 SG_ NEW_SIGNAL_6 : 61|6@0+ (1,0) [0|63] "" XXX
 SG_ NEW_SIGNAL_3 : 71|32@0+ (1,0) [0|4294967295] "" XXX
 SG_ NEW_SIGNAL_2 : 103|32@0+ (1,0) [0|4294967295] "" XXX
 SG_ NEW_SIGNAL_1 : 135|32@0+ (1,0) [0|4294967295] "" XXX
 SG_ NEW_SIGNAL_26 : 199|32@0+ (1,0) [0|4294967295] "" XXX
 SG_ NEW_SIGNAL_25 : 231|32@0+ (1,0) [0|4294967295] "" XXX
 SG_ NEW_SIGNAL_24 : 263|32@0+ (1,0) [0|4294967295] "" XXX

BO_ 768 MEB_ACC_01: 48 XXX
 SG_ NEW_SIGNAL_41 : 66|3@0+ (1,0) [0|7] "" XXX
 SG_ NEW_SIGNAL_4 : 69|1@0+ (1,0) [0|1] "" XXX
 SG_ NEW_SIGNAL_42 : 73|1@0+ (1,0) [0|1] "" XXX
 SG_ ACC_Set_Speed_1 : 79|4@0+ (1,2) [0|15] "" XXX
 SG_ ACC_Set_Speed_2 : 85|6@0+ (5,0) [0|63] "" XXX
 SG_ NEW_SIGNAL_32 : 87|2@0+ (1,0) [0|3] "" XXX
 SG_ NEW_SIGNAL_33 : 95|8@0+ (1,0) [0|255] "" XXX
 SG_ NEW_SIGNAL_2 : 96|1@0+ (1,0) [0|1] "" XXX
 SG_ ACC_Ready : 97|1@0+ (1,0) [0|1] "" XXX
 SG_ NEW_SIGNAL_30 : 98|1@0+ (1,0) [0|1] "" XXX
 SG_ NEW_SIGNAL_22 : 102|1@0+ (1,0) [0|1] "" XXX
 SG_ NEW_SIGNAL_1 : 107|2@0+ (1,0) [0|3] "" XXX
 SG_ NEW_SIGNAL_31 : 109|1@0+ (1,0) [0|1] "" XXX
 SG_ NEW_SIGNAL_3 : 112|1@0+ (1,0) [0|1] "" XXX
 SG_ ACC_Active : 113|1@0+ (1,0) [0|1] "" XXX
 SG_ NEW_SIGNAL_24 : 120|1@0+ (1,0) [0|1] "" XXX
 SG_ NEW_SIGNAL_18 : 121|1@0+ (1,0) [0|1] "" XXX
 SG_ NEW_SIGNAL_5 : 143|4@0+ (1,0) [0|15] "" XXX
 SG_ NEW_SIGNAL_6 : 149|6@0+ (1,0) [0|63] "" XXX
 SG_ NEW_SIGNAL_7 : 150|1@0+ (1,0) [0|1] "" XXX
 SG_ NEW_SIGNAL_8 : 158|7@0+ (1,0) [0|127] "" XXX
 SG_ NEW_SIGNAL_10 : 167|16@0+ (1,0) [0|65535] "" XXX
 SG_ NEW_SIGNAL_9 : 186|1@0+ (1,0) [0|1] "" XXX
 SG_ NEW_SIGNAL_23 : 189|1@0+ (1,0) [0|1] "" XXX
 SG_ NEW_SIGNAL_25 : 208|1@0+ (1,0) [0|1] "" XXX
 SG_ NEW_SIGNAL_11 : 209|1@0+ (1,0) [0|1] "" XXX
 SG_ NEW_SIGNAL_26 : 210|1@0+ (1,0) [0|1] "" XXX
 SG_ NEW_SIGNAL_27 : 224|1@0+ (1,0) [0|1] "" XXX
 SG_ NEW_SIGNAL_13 : 226|1@0+ (1,0) [0|1] "" XXX
 SG_ NEW_SIGNAL_12 : 228|1@0+ (1,0) [0|1] "" XXX
 SG_ NEW_SIGNAL_20 : 247|8@0+ (1,0) [0|255] "" XXX
 SG_ NEW_SIGNAL_21 : 254|7@0+ (1,0) [0|127] "" XXX
 SG_ NEW_SIGNAL_43 : 262|1@0+ (1,0) [0|1] "" XXX
 SG_ NEW_SIGNAL_29 : 265|1@0+ (1,0) [0|1] "" XXX
 SG_ NEW_SIGNAL_14 : 266|1@0+ (1,0) [0|1] "" XXX
 SG_ NEW_SIGNAL_35 : 267|1@0+ (1,0) [0|1] "" XXX
 SG_ ACC_Limiter_Mode : 268|1@0+ (1,0) [0|1] "" XXX
 SG_ NEW_SIGNAL_34 : 270|2@0+ (1,0) [0|3] "" XXX
 SG_ NEW_SIGNAL_17 : 274|1@0+ (1,0) [0|1] "" XXX
 SG_ NEW_SIGNAL_16 : 276|1@0+ (1,0) [0|1] "" XXX
 SG_ NEW_SIGNAL_15 : 279|2@0+ (1,0) [0|3] "" XXX
 SG_ NEW_SIGNAL_36 : 287|1@0+ (1,0) [0|1] "" XXX
 SG_ NEW_SIGNAL_40 : 288|1@0+ (1,0) [0|1] "" XXX
 SG_ NEW_SIGNAL_28 : 293|4@0+ (1,0) [0|15] "" XXX
 SG_ NEW_SIGNAL_37 : 295|2@0+ (1,0) [0|3] "" XXX
 SG_ ACC_Speed : 329|1@0+ (1,0) [0|1] "" XXX
 SG_ NEW_SIGNAL_45 : 331|1@0+ (1,0) [0|1] "" XXX
 SG_ NEW_SIGNAL_19 : 350|7@0+ (1,0) [0|15] "" XXX

BO_ 333 MEB_ACC_02: 32 XXX
 SG_ CHECKSUM : 7|8@0+ (1,0) [0|255] "" XXX
 SG_ COUNTER : 11|4@0+ (1,0) [0|15] "" XXX
 SG_ NEW_SIGNAL_3 : 31|7@0+ (1,0) [0|127] "" XXX
 SG_ NEW_SIGNAL_4 : 34|3@0+ (1,0) [0|7] "" XXX
 SG_ ACC_Active : 47|16@0+ (1,0) [0|65535] "" XXX
 SG_ NEW_SIGNAL_14 : 57|1@0+ (1,0) [0|1] "" XXX
 SG_ NEW_SIGNAL_6 : 59|1@0+ (1,0) [0|1] "" XXX
 SG_ NEW_SIGNAL_13 : 60|1@0+ (1,0) [0|1] "" XXX
 SG_ ACC_Ready : 61|1@0+ (1,0) [0|1] "" XXX
 SG_ NEW_SIGNAL_5 : 62|1@0+ (1,0) [0|1] "" XXX
 SG_ NEW_SIGNAL_7 : 71|7@0+ (1,0) [0|127] "" XXX
 SG_ NEW_SIGNAL_8 : 74|3@0+ (1,0) [0|7] "" XXX
 SG_ ACC_Active_02 : 77|1@0+ (1,0) [0|1] "" XXX
 SG_ NEW_SIGNAL_15 : 79|1@0+ (1,0) [0|1] "" XXX
 SG_ NEW_SIGNAL_9 : 87|7@0+ (1,0) [0|127] "" XXX
 SG_ NEW_SIGNAL_10 : 92|1@0+ (1,0) [0|1] "" XXX
 SG_ NEW_SIGNAL_12 : 232|1@0+ (1,0) [0|1] "" XXX
 SG_ NEW_SIGNAL_11 : 235|1@0+ (1,0) [0|1] "" XXX

VAL_ 173 GE_Fahrstufe 5 "P" 6 "R" 7 "N" 8 "D" 9 "S" 10 "E" 13 "T" 14 "T" ;
VAL_ 159 EPS_HCA_Status 0 "disabled" 1 "initializing" 2 "fault" 3 "ready" 4 "rejected" 5 "active" 8 "preempted" ;
